AUTOSAR XML (schema 4-3-0)
package /CAN4/ISignalGroup
  12 x i signal group:
    CAN4_SG_FD4_C100_0: i-signal=[CAN4_DCDCEnDemand, CAN4_EACSpdDemand, CAN4_FDC_CHA_EACEnDemand_Cmd, CAN4_FDC_EHPS_EnDemand_Cmd, CAN4_FDC_EHPS_SpdDemand_Cmd, CAN4_VCULife2], system-signal-group=CAN4_SG_FD4_C100_0
    CAN4_SG_FD4_C10_0: i-signal=[CAN4_ACHVPwrOnOffReq, CAN4_MCUHVPwrOnOffReq, CAN4_VCULife1, CAN4_VCU_DCDCEACEHPSRlyEn_cmd, CAN4_VCU_DeFogTMSRlyEn_cmd], system-signal-group=CAN4_SG_FD4_C10_0
    CAN4_SG_FD4_C200_0: i-signal=[CAN4_SysPowerMode, CAN4_VCUIGNSta, CAN4_VCUIRCSta], system-signal-group=CAN4_SG_FD4_C200_0
    CAN4_SG_FD4_CE100_0: i-signal=[CAN4_FDC_BCM_BSD_Buzzer_Cmd, CAN4_FDC_BCM_Brake_Cmd, CAN4_FDC_BCM_CallBell_Cmd, CAN4_FDC_BCM_DVRSignalL_Cmd, CAN4_FDC_BCM_DVRSignalR_Cmd, CAN4_FDC_BCM_EmExitSW_Sta, CAN4_FDC_BCM_EmSV_Cmd, CAN4_FDC_BCM_FDCloseSV_Cmd, CAN4_FDC_BCM_FDOpenSV_Cmd, CAN4_FDC_BCM_FDoor_Sta, CAN4_FDC_BCM_HBeam_Cmd, CAN4_FDC_BCM_InnerBuzzerMode_Sta, CAN4_FDC_BCM_InnerBuzzer_Cmd, CAN4_FDC_BCM_InnerCallBell_Cmd, CAN4_FDC_BCM_LBSDR_Cmd, CAN4_FDC_BCM_LBSDY_Cmd, CAN4_FDC_BCM_LBeam_Cmd, CAN4_FDC_BCM_LDRL_Cmd, CAN4_FDC_BCM_LTurnLp_Cmd, CAN4_FDC_BCM_MDCloseSV_Cmd, CAN4_FDC_BCM_MDOpenSV_Cmd, CAN4_FDC_BCM_MDoor_Sta, CAN4_FDC_BCM_OutDoorOpenSW_Sta, CAN4_FDC_BCM_PLamp_Cmd, CAN4_FDC_BCM_RBSDR_Cmd, CAN4_FDC_BCM_RBSDY_Cmd, CAN4_FDC_BCM_RDRL_Cmd, CAN4_FDC_BCM_RDoor_Sta, CAN4_FDC_BCM_RFLamp_Cmd, CAN4_FDC_BCM_RGear_Sta, CAN4_FDC_BCM_RTurnLp_Cmd, CAN4_FDC_BCM_RoomLpAmb_Cmd, CAN4_FDC_BCM_SLTLp_Cmd, CAN4_FDC_BCM_SMKL_Cmd, CAN4_FDC_BCM_SMKR_Cmd, CAN4_FDC_BCM_SRTLp_Cmd, CAN4_FDC_BCM_STOPBALL_Cmd, CAN4_FDC_BCM_Stop_IND_Cmd, CAN4_FDC_BCM_TurnLpPattern_Sta, CAN4_FDC_BCM_Washer_Cmd, CAN4_FDC_BCM_WiperH_Cmd, CAN4_FDC_BCM_WiperL_Cmd, CAN4_VCUKeyStatus], system-signal-group=CAN4_SG_FD4_CE100_0
    CAN4_SG_FD4_CE100_1: i-signal=[CAN4_FDC_BCM_FRoomLp_Cmd, CAN4_FDC_BCM_MRoomLp_Cmd, CAN4_FDC_BCM_RRoomLp_Cmd, CAN4_FDC_THCM_CoolFanReq_Cmd], system-signal-group=CAN4_SG_FD4_CE100_1
    CAN4_SG_ZFR_C100_0: i-signal=CAN4_ParkBrakeSW, system-signal-group=CAN4_SG_ZFR_C100_0
    CAN4_SG_ZFR_C5000_0: i-signal=[CAN4_ZFR_CHASSIS_LiningWearFL_Sta, CAN4_ZFR_CHASSIS_LiningWearFR_Sta], system-signal-group=CAN4_SG_ZFR_C5000_0
    CAN4_SG_ZFR_CE100_0: i-signal=[CAN4_AirPressureFC2, CAN4_ZFR_BCM_AutoLightSW_Sta, CAN4_ZFR_BCM_BSD_Dimmer_Sta, CAN4_ZFR_BCM_BacklightDuty_Sta, CAN4_ZFR_BCM_Brake_Sta, CAN4_ZFR_BCM_DVRMidDoor_Sta, CAN4_ZFR_BCM_DVRSignalL_Sta, CAN4_ZFR_BCM_DVRSignalR_Sta, CAN4_ZFR_BCM_DVRSignalReverse_Sta, CAN4_ZFR_BCM_HBeamSW_Sta, CAN4_ZFR_BCM_HBeam_Sta, CAN4_ZFR_BCM_HeadLpSW_Sta, CAN4_ZFR_BCM_HornSW_Sta, CAN4_ZFR_BCM_LBSDR_Sta, CAN4_ZFR_BCM_LBSDY_Sta, CAN4_ZFR_BCM_LBeam_Sta, CAN4_ZFR_BCM_LDRL_Sta, CAN4_ZFR_BCM_LFTurnLpC_Sta, CAN4_ZFR_BCM_LFTurnLp_Sta, CAN4_ZFR_BCM_LightSensorV_Sta, CAN4_ZFR_BCM_PLamp_Sta, CAN4_ZFR_BCM_PosLpSW_Sta, CAN4_ZFR_BCM_RBSDR_Sta, CAN4_ZFR_BCM_RBSDY_Sta, CAN4_ZFR_BCM_RDRL_Sta, CAN4_ZFR_BCM_RFTurnLpC_Sta, CAN4_ZFR_BCM_RFTurnLp_Sta, CAN4_ZFR_BCM_RFogLp_SW_Sta, CAN4_ZFR_BCM_Seatbelt_Sta, CAN4_ZFR_BCM_TurnBuzzer_Sta, CAN4_ZFR_BCM_WasherSW_Sta, CAN4_ZFR_BCM_Washer_Sta, CAN4_ZFR_BCM_WiperAS_Sta, CAN4_ZFR_BCM_WiperHSW_Sta, CAN4_ZFR_BCM_WiperH_Sta, CAN4_ZFR_BCM_WiperLSW_Sta, CAN4_ZFR_BCM_WiperL_Sta], system-signal-group=CAN4_SG_ZFR_CE100_0
    CAN4_SG_ZRR_C5000_0: i-signal=[CAN4_ZRR_CHASSIS_LiningWearRL_Sta, CAN4_ZRR_CHASSIS_LiningWearRR_Sta], system-signal-group=CAN4_SG_ZRR_C5000_0
    CAN4_SG_ZRR_CE100_0: i-signal=CAN4_ZRR_BCM_AllDoor_Sta, system-signal-group=CAN4_SG_ZRR_CE100_0
    CAN4_SG_ZRR_CE100_1: i-signal=[CAN4_AirPressurePC3, CAN4_AirPressureRC1, CAN4_FDC_CHASSIS_VCUEACPress_Sta, CAN4_ZRR_BCM_BrakeLp_Sta, CAN4_ZRR_BCM_CallingSW_Sta, CAN4_ZRR_BCM_EmLight_Sta, CAN4_ZRR_BCM_EmSV_Sta, CAN4_ZRR_BCM_FDCloseSV_Sta, CAN4_ZRR_BCM_FDOpenSV_Sta, CAN4_ZRR_BCM_FDoorAP_Sta, CAN4_ZRR_BCM_LRTurnLpC_Sta, CAN4_ZRR_BCM_LRTurnLp_Sta, CAN4_ZRR_BCM_MDCloseSV_Sta, CAN4_ZRR_BCM_MDOpenSV_Sta, CAN4_ZRR_BCM_MDoorAP_Sta, CAN4_ZRR_BCM_PLamp_Sta, CAN4_ZRR_BCM_RFLamp_Sta, CAN4_ZRR_BCM_RRTurnLpC_Sta, CAN4_ZRR_BCM_RRTurnLp_Sta, CAN4_ZRR_BCM_ReverseBuz_Sta, CAN4_ZRR_BCM_ReverseLp_Sta, CAN4_ZRR_BCM_RoomLpAmb_Sta, CAN4_ZRR_BCM_SLTLp_Sta, CAN4_ZRR_BCM_SMKL_Sta, CAN4_ZRR_BCM_SMKR_Sta, CAN4_ZRR_BCM_SRTLp_Sta, CAN4_ZRR_BCM_STOPSW2_Sta, CAN4_ZRR_BCM_STOPSW_Sta, CAN4_ZRR_BCM_StopLight_Sta, CAN4_ZRR_BCM_TurnBuzzer_Sta], system-signal-group=CAN4_SG_ZRR_CE100_1
    CAN4_SG_zGW_CANRr1_C50_0: i-signal=[CAN4_DCDC_En_Sta, CAN4_DCDC_ErrLv_Sta, CAN4_DCDC_LifeSig_Sta, CAN4_DCDC_OutVol_Sta, CAN4_DCDC_Temp_Sta, CAN4_EAC_En_Sta, CAN4_EAC_ErrLv_Sta, CAN4_EAC_InvTemp_Sta, CAN4_EAC_LifeSig_Sta, CAN4_EHPS_En_Sta, CAN4_EHPS_ErrLv_Sta, CAN4_EHPS_InvTemp_Sta, CAN4_EHPS_LifeSig_Sta, CAN4_EHPS_MotorSpd_Sta, CAN4_PDU_ACRly_Sta, CAN4_PDU_DCDCEACEHPSHVLoop_Sta, CAN4_PDU_DCDCEACEHPSPreRly_Sta, CAN4_PDU_DCDCEACEHPSRly_Sta, CAN4_PDU_DeFogTMSRly_Sta, CAN4_PDU_HVIL_Sta, CAN4_PDU_LifeSig_Sta, CAN4_PDU_MCUHVLoop_Sta, CAN4_PDU_MCUPosRly_Sta, CAN4_PDU_MCUPreRly_Sta, CAN4_PDU_SelfChk_Sta], system-signal-group=CAN4_SG_zGW_CANRr1_C50_0
package /CAN4/Cluster
  can cluster CAN4: baudrate=500, can-fd-baudrate=2000
    can physical channel CAN4: comm-connectors=ConnCAN4
      frame CAN4_DiagFuncReqFT: id 0x7D0, frame-length=8, can-addressing-mode=STANDARD, can-fd-frame-support=false, can-frame-rx-behavior=CAN-20, can-frame-tx-behavior=CAN-20
        n pdu CAN4_DiagFuncReqFT: length=8
      frame CAN4_DiagPhysReqToZONE_FR: id 0x684, frame-length=64, can-addressing-mode=STANDARD, can-fd-frame-support=true, can-frame-rx-behavior=CAN-FD, can-frame-tx-behavior=CAN-FD
        n pdu CAN4_DiagPhysReqToZONE_FR: length=8
      frame CAN4_DiagPhysReqToZONE_RR: id 0x6E4, frame-length=64, can-addressing-mode=STANDARD, can-fd-frame-support=true, can-frame-rx-behavior=CAN-FD, can-frame-tx-behavior=CAN-FD
        n pdu CAN4_DiagPhysReqToZONE_RR: length=8
      frame CAN4_DiagRespFromZONE_FR: id 0x604, frame-length=64, can-addressing-mode=STANDARD, can-fd-frame-support=true, can-frame-rx-behavior=CAN-FD, can-frame-tx-behavior=CAN-FD
        n pdu CAN4_DiagRespFromZONE_FR: length=8
      frame CAN4_DiagRespFromZONE_RR: id 0x664, frame-length=64, can-addressing-mode=STANDARD, can-fd-frame-support=true, can-frame-rx-behavior=CAN-FD, can-frame-tx-behavior=CAN-FD
        n pdu CAN4_DiagRespFromZONE_RR: length=8
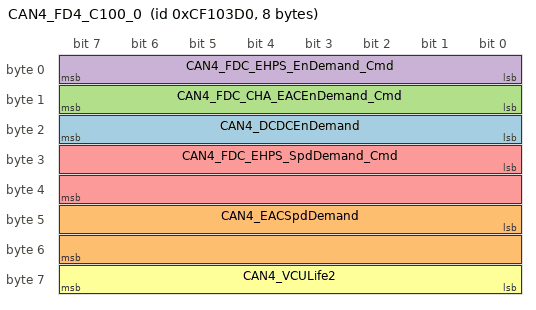
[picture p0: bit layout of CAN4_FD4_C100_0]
      frame CAN4_FD4_C100_0: id 0xCF103D0, frame-length=8, can-addressing-mode=EXTENDED, can-fd-frame-support=false, can-frame-rx-behavior=CAN-20, can-frame-tx-behavior=CAN-20
        pdu CAN4_FD4_C100_0: length=8, minimum-delay=0.0, transmission-mode-true-timing=cyclic-timing=time-period=0.1, unused-bit-pattern=0
          mapping CAN4_SG_FD4_C100_0: i-signal-group=CAN4_SG_FD4_C100_0, start-position=0, transfer-property=PENDING
          signal CAN4_DCDCEnDemand: start 16, 8 bit, little-endian, i-signal-type=PRIMITIVE, init-value=constant-reference=Init_CAN4_DCDCEnDemand, base-type=uint8, implementation-data-type=uint8, transfer-property=PENDING
          signal CAN4_EACSpdDemand: start 40, 16 bit, little-endian, i-signal-type=PRIMITIVE, init-value=constant-reference=Init_CAN4_EACSpdDemand, base-type=uint16, implementation-data-type=uint16, transfer-property=PENDING
          signal CAN4_FDC_CHA_EACEnDemand_Cmd: start 8, 8 bit, little-endian, i-signal-type=PRIMITIVE, init-value=constant-reference=Init_CAN4_FDC_CHA_EACEnDemand_Cmd, base-type=uint8, implementation-data-type=uint8, transfer-property=PENDING
          signal CAN4_FDC_EHPS_EnDemand_Cmd: start 0, 8 bit, little-endian, i-signal-type=PRIMITIVE, init-value=constant-reference=Init_CAN4_FDC_EHPS_EnDemand_Cmd, base-type=uint8, implementation-data-type=uint8, transfer-property=PENDING
          signal CAN4_FDC_EHPS_SpdDemand_Cmd: start 24, 16 bit, little-endian, i-signal-type=PRIMITIVE, init-value=constant-reference=Init_CAN4_FDC_EHPS_SpdDemand_Cmd, base-type=uint16, implementation-data-type=uint16, transfer-property=PENDING
          signal CAN4_VCULife2: start 56, 8 bit, little-endian, i-signal-type=PRIMITIVE, init-value=constant-reference=Init_CAN4_VCULife2, base-type=uint8, implementation-data-type=uint8, transfer-property=PENDING
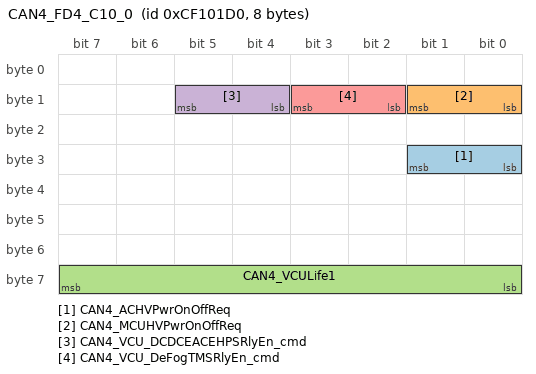
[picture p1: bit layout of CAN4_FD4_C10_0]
      frame CAN4_FD4_C10_0: id 0xCF101D0, frame-length=8, can-addressing-mode=EXTENDED, can-fd-frame-support=false, can-frame-rx-behavior=CAN-20, can-frame-tx-behavior=CAN-20
        pdu CAN4_FD4_C10_0: length=8, minimum-delay=0.0, transmission-mode-true-timing=cyclic-timing=time-period=0.01, unused-bit-pattern=0
          mapping CAN4_SG_FD4_C10_0: i-signal-group=CAN4_SG_FD4_C10_0, start-position=0, transfer-property=PENDING
          signal CAN4_ACHVPwrOnOffReq: start 24, 2 bit, little-endian, i-signal-type=PRIMITIVE, init-value=constant-reference=Init_CAN4_ACHVPwrOnOffReq, base-type=uint8, implementation-data-type=uint8, transfer-property=PENDING
          signal CAN4_MCUHVPwrOnOffReq: start 8, 2 bit, little-endian, i-signal-type=PRIMITIVE, init-value=constant-reference=Init_CAN4_MCUHVPwrOnOffReq, base-type=uint8, implementation-data-type=uint8, transfer-property=PENDING
          signal CAN4_VCULife1: start 56, 8 bit, little-endian, i-signal-type=PRIMITIVE, init-value=constant-reference=Init_CAN4_VCULife1, base-type=uint8, implementation-data-type=uint8, transfer-property=PENDING
          signal CAN4_VCU_DCDCEACEHPSRlyEn_cmd: start 12, 2 bit, little-endian, i-signal-type=PRIMITIVE, init-value=constant-reference=Init_CAN4_VCU_DCDCEACEHPSRlyEn_cmd, base-type=uint8, implementation-data-type=uint8, transfer-property=PENDING
          signal CAN4_VCU_DeFogTMSRlyEn_cmd: start 10, 2 bit, little-endian, i-signal-type=PRIMITIVE, init-value=constant-reference=Init_CAN4_VCU_DeFogTMSRlyEn_cmd, base-type=uint8, implementation-data-type=uint8, transfer-property=PENDING
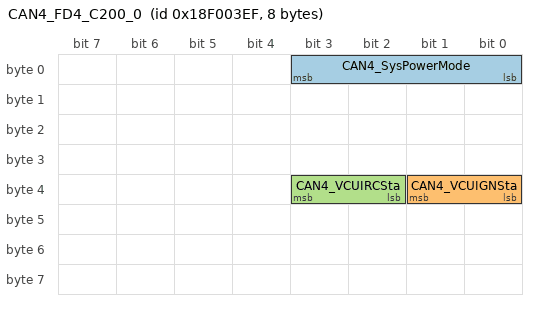
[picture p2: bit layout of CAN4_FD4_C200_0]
      frame CAN4_FD4_C200_0: id 0x18F003EF, frame-length=8, can-addressing-mode=EXTENDED, can-fd-frame-support=false, can-frame-rx-behavior=CAN-20, can-frame-tx-behavior=CAN-20
        pdu CAN4_FD4_C200_0: length=8, minimum-delay=0.0, transmission-mode-true-timing=cyclic-timing=time-period=0.2, unused-bit-pattern=0
          mapping CAN4_SG_FD4_C200_0: i-signal-group=CAN4_SG_FD4_C200_0, start-position=0, transfer-property=PENDING
          signal CAN4_SysPowerMode: start 0, 4 bit, little-endian, i-signal-type=PRIMITIVE, init-value=constant-reference=Init_CAN4_SysPowerMode, base-type=uint8, implementation-data-type=uint8, transfer-property=PENDING
          signal CAN4_VCUIGNSta: start 32, 2 bit, little-endian, i-signal-type=PRIMITIVE, init-value=constant-reference=Init_CAN4_VCUIGNSta, base-type=uint8, implementation-data-type=uint8, transfer-property=PENDING
          signal CAN4_VCUIRCSta: start 34, 2 bit, little-endian, i-signal-type=PRIMITIVE, init-value=constant-reference=Init_CAN4_VCUIRCSta, base-type=uint8, implementation-data-type=uint8, transfer-property=PENDING
      frame CAN4_FD4_CE100_0: id 0x209, frame-length=32, can-addressing-mode=STANDARD, can-fd-frame-support=true, can-frame-rx-behavior=CAN-FD, can-frame-tx-behavior=CAN-FD
        pdu CAN4_FD4_CE100_0: length=32, minimum-delay=0.0, transmission-mode-true-timing={cyclic-timing=time-period=0.1, event-controlled-timing={number-of-repetitions=0, repetition-period=0}}, unused-bit-pattern=0
          mapping CAN4_SG_FD4_CE100_0: i-signal-group=CAN4_SG_FD4_CE100_0, start-position=0, transfer-property=TRIGGERED-ON-CHANGE
          signal CAN4_FDC_BCM_BSD_Buzzer_Cmd: start 39, 1 bit, big-endian, i-signal-type=PRIMITIVE, init-value=constant-reference=Init_CAN4_FDC_BCM_BSD_Buzzer_Cmd, base-type=uint8, implementation-data-type=uint8, transfer-property=TRIGGERED-ON-CHANGE
          signal CAN4_FDC_BCM_Brake_Cmd: start 30, 1 bit, big-endian, i-signal-type=PRIMITIVE, init-value=constant-reference=Init_CAN4_FDC_BCM_Brake_Cmd, base-type=uint8, implementation-data-type=uint8, transfer-property=TRIGGERED-ON-CHANGE
          signal CAN4_FDC_BCM_CallBell_Cmd: start 20, 1 bit, big-endian, i-signal-type=PRIMITIVE, init-value=constant-reference=Init_CAN4_FDC_BCM_CallBell_Cmd, base-type=uint8, implementation-data-type=uint8, transfer-property=TRIGGERED-ON-CHANGE
          signal CAN4_FDC_BCM_DVRSignalL_Cmd: start 52, 1 bit, big-endian, i-signal-type=PRIMITIVE, init-value=constant-reference=Init_CAN4_FDC_BCM_DVRSignalL_Cmd, base-type=uint8, implementation-data-type=uint8, transfer-property=PENDING
          signal CAN4_FDC_BCM_DVRSignalR_Cmd: start 51, 1 bit, big-endian, i-signal-type=PRIMITIVE, init-value=constant-reference=Init_CAN4_FDC_BCM_DVRSignalR_Cmd, base-type=uint8, implementation-data-type=uint8, transfer-property=PENDING
          signal CAN4_FDC_BCM_EmExitSW_Sta: start 9, 1 bit, big-endian, i-signal-type=PRIMITIVE, init-value=constant-reference=Init_CAN4_FDC_BCM_EmExitSW_Sta, base-type=uint8, implementation-data-type=uint8, transfer-property=TRIGGERED-ON-CHANGE
          signal CAN4_FDC_BCM_EmSV_Cmd: start 6, 1 bit, big-endian, i-signal-type=PRIMITIVE, init-value=constant-reference=Init_CAN4_FDC_BCM_EmSV_Cmd, base-type=uint8, implementation-data-type=uint8, transfer-property=TRIGGERED-ON-CHANGE
          signal CAN4_FDC_BCM_FDCloseSV_Cmd: start 3, 1 bit, big-endian, i-signal-type=PRIMITIVE, init-value=constant-reference=Init_CAN4_FDC_BCM_FDCloseSV_Cmd, base-type=uint8, implementation-data-type=uint8, transfer-property=TRIGGERED-ON-CHANGE
          signal CAN4_FDC_BCM_FDOpenSV_Cmd: start 2, 1 bit, big-endian, i-signal-type=PRIMITIVE, init-value=constant-reference=Init_CAN4_FDC_BCM_FDOpenSV_Cmd, base-type=uint8, implementation-data-type=uint8, transfer-property=TRIGGERED-ON-CHANGE
          signal CAN4_FDC_BCM_FDoor_Sta: start 45, 1 bit, big-endian, i-signal-type=PRIMITIVE, init-value=constant-reference=Init_CAN4_FDC_BCM_FDoor_Sta, base-type=uint8, implementation-data-type=uint8, transfer-property=TRIGGERED-ON-CHANGE
          signal CAN4_FDC_BCM_HBeam_Cmd: start 40, 1 bit, big-endian, i-signal-type=PRIMITIVE, init-value=constant-reference=Init_CAN4_FDC_BCM_HBeam_Cmd, base-type=uint8, implementation-data-type=uint8, transfer-property=TRIGGERED-ON-CHANGE
          signal CAN4_FDC_BCM_InnerBuzzerMode_Sta: start 23, 3 bit, big-endian, i-signal-type=PRIMITIVE, init-value=constant-reference=Init_CAN4_FDC_BCM_InnerBuzzerMode_Sta, base-type=uint8, implementation-data-type=uint8, transfer-property=TRIGGERED-ON-CHANGE
          signal CAN4_FDC_BCM_InnerBuzzer_Cmd: start 8, 1 bit, big-endian, i-signal-type=PRIMITIVE, init-value=constant-reference=Init_CAN4_FDC_BCM_InnerBuzzer_Cmd, base-type=uint8, implementation-data-type=uint8, transfer-property=TRIGGERED-ON-CHANGE
          signal CAN4_FDC_BCM_InnerCallBell_Cmd: start 19, 1 bit, big-endian, i-signal-type=PRIMITIVE, init-value=constant-reference=Init_CAN4_FDC_BCM_InnerCallBell_Cmd, base-type=uint8, implementation-data-type=uint8, transfer-property=TRIGGERED-ON-CHANGE
          signal CAN4_FDC_BCM_LBSDR_Cmd: start 35, 1 bit, big-endian, i-signal-type=PRIMITIVE, init-value=constant-reference=Init_CAN4_FDC_BCM_LBSDR_Cmd, base-type=uint8, implementation-data-type=uint8, transfer-property=TRIGGERED-ON-CHANGE
          signal CAN4_FDC_BCM_LBSDY_Cmd: start 36, 1 bit, big-endian, i-signal-type=PRIMITIVE, init-value=constant-reference=Init_CAN4_FDC_BCM_LBSDY_Cmd, base-type=uint8, implementation-data-type=uint8, transfer-property=TRIGGERED-ON-CHANGE
          signal CAN4_FDC_BCM_LBeam_Cmd: start 55, 1 bit, big-endian, i-signal-type=PRIMITIVE, init-value=constant-reference=Init_CAN4_FDC_BCM_LBeam_Cmd, base-type=uint8, implementation-data-type=uint8, transfer-property=TRIGGERED-ON-CHANGE
          signal CAN4_FDC_BCM_LDRL_Cmd: start 42, 1 bit, big-endian, i-signal-type=PRIMITIVE, init-value=constant-reference=Init_CAN4_FDC_BCM_LDRL_Cmd, base-type=uint8, implementation-data-type=uint8, transfer-property=TRIGGERED-ON-CHANGE
          signal CAN4_FDC_BCM_LTurnLp_Cmd: start 54, 1 bit, big-endian, i-signal-type=PRIMITIVE, init-value=constant-reference=Init_CAN4_FDC_BCM_LTurnLp_Cmd, base-type=uint8, implementation-data-type=uint8, transfer-property=PENDING
          signal CAN4_FDC_BCM_MDCloseSV_Cmd: start 5, 1 bit, big-endian, i-signal-type=PRIMITIVE, init-value=constant-reference=Init_CAN4_FDC_BCM_MDCloseSV_Cmd, base-type=uint8, implementation-data-type=uint8, transfer-property=TRIGGERED-ON-CHANGE
          signal CAN4_FDC_BCM_MDOpenSV_Cmd: start 4, 1 bit, big-endian, i-signal-type=PRIMITIVE, init-value=constant-reference=Init_CAN4_FDC_BCM_MDOpenSV_Cmd, base-type=uint8, implementation-data-type=uint8, transfer-property=TRIGGERED-ON-CHANGE
          signal CAN4_FDC_BCM_MDoor_Sta: start 44, 1 bit, big-endian, i-signal-type=PRIMITIVE, init-value=constant-reference=Init_CAN4_FDC_BCM_MDoor_Sta, base-type=uint8, implementation-data-type=uint8, transfer-property=TRIGGERED-ON-CHANGE
          signal CAN4_FDC_BCM_OutDoorOpenSW_Sta: start 1, 2 bit, big-endian, i-signal-type=PRIMITIVE, init-value=constant-reference=Init_CAN4_FDC_BCM_OutDoorOpenSW_Sta, base-type=uint8, implementation-data-type=uint8, transfer-property=TRIGGERED-ON-CHANGE
          signal CAN4_FDC_BCM_PLamp_Cmd: start 41, 1 bit, big-endian, i-signal-type=PRIMITIVE, init-value=constant-reference=Init_CAN4_FDC_BCM_PLamp_Cmd, base-type=uint8, implementation-data-type=uint8, transfer-property=TRIGGERED-ON-CHANGE
          signal CAN4_FDC_BCM_RBSDR_Cmd: start 37, 1 bit, big-endian, i-signal-type=PRIMITIVE, init-value=constant-reference=Init_CAN4_FDC_BCM_RBSDR_Cmd, base-type=uint8, implementation-data-type=uint8, transfer-property=TRIGGERED-ON-CHANGE
          signal CAN4_FDC_BCM_RBSDY_Cmd: start 38, 1 bit, big-endian, i-signal-type=PRIMITIVE, init-value=constant-reference=Init_CAN4_FDC_BCM_RBSDY_Cmd, base-type=uint8, implementation-data-type=uint8, transfer-property=TRIGGERED-ON-CHANGE
          signal CAN4_FDC_BCM_RDRL_Cmd: start 43, 1 bit, big-endian, i-signal-type=PRIMITIVE, init-value=constant-reference=Init_CAN4_FDC_BCM_RDRL_Cmd, base-type=uint8, implementation-data-type=uint8, transfer-property=TRIGGERED-ON-CHANGE
          signal CAN4_FDC_BCM_RDoor_Sta: start 46, 1 bit, big-endian, i-signal-type=PRIMITIVE, init-value=constant-reference=Init_CAN4_FDC_BCM_RDoor_Sta, base-type=uint8, implementation-data-type=uint8, transfer-property=TRIGGERED-ON-CHANGE
          signal CAN4_FDC_BCM_RFLamp_Cmd: start 31, 1 bit, big-endian, i-signal-type=PRIMITIVE, init-value=constant-reference=Init_CAN4_FDC_BCM_RFLamp_Cmd, base-type=uint8, implementation-data-type=uint8, transfer-property=TRIGGERED-ON-CHANGE
          signal CAN4_FDC_BCM_RGear_Sta: start 47, 1 bit, big-endian, i-signal-type=PRIMITIVE, init-value=constant-reference=Init_CAN4_FDC_BCM_RGear_Sta, base-type=uint8, implementation-data-type=uint8, transfer-property=TRIGGERED-ON-CHANGE
          signal CAN4_FDC_BCM_RTurnLp_Cmd: start 53, 1 bit, big-endian, i-signal-type=PRIMITIVE, init-value=constant-reference=Init_CAN4_FDC_BCM_RTurnLp_Cmd, base-type=uint8, implementation-data-type=uint8, transfer-property=PENDING
          signal CAN4_FDC_BCM_RoomLpAmb_Cmd: start 25, 1 bit, big-endian, i-signal-type=PRIMITIVE, init-value=constant-reference=Init_CAN4_FDC_BCM_RoomLpAmb_Cmd, base-type=uint8, implementation-data-type=uint8, transfer-property=TRIGGERED-ON-CHANGE
          signal CAN4_FDC_BCM_SLTLp_Cmd: start 29, 1 bit, big-endian, i-signal-type=PRIMITIVE, init-value=constant-reference=Init_CAN4_FDC_BCM_SLTLp_Cmd, base-type=uint8, implementation-data-type=uint8, transfer-property=TRIGGERED-ON-CHANGE
          signal CAN4_FDC_BCM_SMKL_Cmd: start 26, 1 bit, big-endian, i-signal-type=PRIMITIVE, init-value=constant-reference=Init_CAN4_FDC_BCM_SMKL_Cmd, base-type=uint8, implementation-data-type=uint8, transfer-property=TRIGGERED-ON-CHANGE
          signal CAN4_FDC_BCM_SMKR_Cmd: start 27, 1 bit, big-endian, i-signal-type=PRIMITIVE, init-value=constant-reference=Init_CAN4_FDC_BCM_SMKR_Cmd, base-type=uint8, implementation-data-type=uint8, transfer-property=TRIGGERED-ON-CHANGE
          signal CAN4_FDC_BCM_SRTLp_Cmd: start 28, 1 bit, big-endian, i-signal-type=PRIMITIVE, init-value=constant-reference=Init_CAN4_FDC_BCM_SRTLp_Cmd, base-type=uint8, implementation-data-type=uint8, transfer-property=TRIGGERED-ON-CHANGE
          signal CAN4_FDC_BCM_STOPBALL_Cmd: start 18, 1 bit, big-endian, i-signal-type=PRIMITIVE, init-value=constant-reference=Init_CAN4_FDC_BCM_STOPBALL_Cmd, base-type=uint8, implementation-data-type=uint8, transfer-property=TRIGGERED-ON-CHANGE
          signal CAN4_FDC_BCM_Stop_IND_Cmd: start 24, 1 bit, big-endian, i-signal-type=PRIMITIVE, init-value=constant-reference=Init_CAN4_FDC_BCM_Stop_IND_Cmd, base-type=uint8, implementation-data-type=uint8, transfer-property=TRIGGERED-ON-CHANGE
          signal CAN4_FDC_BCM_TurnLpPattern_Sta: start 17, 2 bit, big-endian, i-signal-type=PRIMITIVE, init-value=constant-reference=Init_CAN4_FDC_BCM_TurnLpPattern_Sta, base-type=uint8, implementation-data-type=uint8, transfer-property=TRIGGERED-ON-CHANGE
          signal CAN4_FDC_BCM_Washer_Cmd: start 34, 1 bit, big-endian, i-signal-type=PRIMITIVE, init-value=constant-reference=Init_CAN4_FDC_BCM_Washer_Cmd, base-type=uint8, implementation-data-type=uint8, transfer-property=TRIGGERED-ON-CHANGE
          signal CAN4_FDC_BCM_WiperH_Cmd: start 32, 1 bit, big-endian, i-signal-type=PRIMITIVE, init-value=constant-reference=Init_CAN4_FDC_BCM_WiperH_Cmd, base-type=uint8, implementation-data-type=uint8, transfer-property=TRIGGERED-ON-CHANGE
          signal CAN4_FDC_BCM_WiperL_Cmd: start 33, 1 bit, big-endian, i-signal-type=PRIMITIVE, init-value=constant-reference=Init_CAN4_FDC_BCM_WiperL_Cmd, base-type=uint8, implementation-data-type=uint8, transfer-property=TRIGGERED-ON-CHANGE
          signal CAN4_VCUKeyStatus: start 11, 2 bit, big-endian, i-signal-type=PRIMITIVE, init-value=constant-reference=Init_CAN4_VCUKeyStatus, base-type=uint8, implementation-data-type=uint8, transfer-property=PENDING
      frame CAN4_FD4_CE100_1: id 0x210, frame-length=32, can-addressing-mode=STANDARD, can-fd-frame-support=true, can-frame-rx-behavior=CAN-FD, can-frame-tx-behavior=CAN-FD
        pdu CAN4_FD4_CE100_1: length=32, minimum-delay=0.0, transmission-mode-true-timing={cyclic-timing=time-period=0.1, event-controlled-timing={number-of-repetitions=0, repetition-period=0}}, unused-bit-pattern=0
          mapping CAN4_SG_FD4_CE100_1: i-signal-group=CAN4_SG_FD4_CE100_1, start-position=0, transfer-property=TRIGGERED-ON-CHANGE
          signal CAN4_FDC_BCM_FRoomLp_Cmd: start 39, 7 bit, big-endian, i-signal-type=PRIMITIVE, init-value=constant-reference=Init_CAN4_FDC_BCM_FRoomLp_Cmd, base-type=uint8, implementation-data-type=uint8, transfer-property=PENDING
          signal CAN4_FDC_BCM_MRoomLp_Cmd: start 47, 7 bit, big-endian, i-signal-type=PRIMITIVE, init-value=constant-reference=Init_CAN4_FDC_BCM_MRoomLp_Cmd, base-type=uint8, implementation-data-type=uint8, transfer-property=PENDING
          signal CAN4_FDC_BCM_RRoomLp_Cmd: start 7, 7 bit, big-endian, i-signal-type=PRIMITIVE, init-value=constant-reference=Init_CAN4_FDC_BCM_RRoomLp_Cmd, base-type=uint8, implementation-data-type=uint8, transfer-property=PENDING
          signal CAN4_FDC_THCM_CoolFanReq_Cmd: start 15, 8 bit, big-endian, i-signal-type=PRIMITIVE, init-value=constant-reference=Init_CAN4_FDC_THCM_CoolFanReq_Cmd, base-type=uint8, implementation-data-type=uint8, transfer-property=TRIGGERED-ON-CHANGE
      frame CAN4_ZFR_C100_0: id 0x203, frame-length=32, can-addressing-mode=STANDARD, can-fd-frame-support=true, can-frame-rx-behavior=CAN-FD, can-frame-tx-behavior=CAN-FD
        pdu CAN4_ZFR_C100_0: length=32, minimum-delay=0.0, transmission-mode-true-timing=cyclic-timing=time-period=0.1, unused-bit-pattern=0
          mapping CAN4_SG_ZFR_C100_0: i-signal-group=CAN4_SG_ZFR_C100_0, start-position=0, transfer-property=PENDING
          signal CAN4_ParkBrakeSW: start 7, 2 bit, big-endian, i-signal-type=PRIMITIVE, init-value=constant-reference=Init_CAN4_ParkBrakeSW, base-type=uint8, implementation-data-type=uint8, transfer-property=PENDING
      frame CAN4_ZFR_C5000_0: id 0x201, frame-length=32, can-addressing-mode=STANDARD, can-fd-frame-support=true, can-frame-rx-behavior=CAN-FD, can-frame-tx-behavior=CAN-FD
        pdu CAN4_ZFR_C5000_0: length=32, minimum-delay=0.0, transmission-mode-true-timing=cyclic-timing=time-period=5, unused-bit-pattern=0
          mapping CAN4_SG_ZFR_C5000_0: i-signal-group=CAN4_SG_ZFR_C5000_0, start-position=0, transfer-property=PENDING
          signal CAN4_ZFR_CHASSIS_LiningWearFL_Sta: start 7, 1 bit, big-endian, i-signal-type=PRIMITIVE, init-value=constant-reference=Init_CAN4_ZFR_CHASSIS_LiningWearFL_Sta, base-type=uint8, implementation-data-type=uint8, transfer-property=PENDING
          signal CAN4_ZFR_CHASSIS_LiningWearFR_Sta: start 6, 1 bit, big-endian, i-signal-type=PRIMITIVE, init-value=constant-reference=Init_CAN4_ZFR_CHASSIS_LiningWearFR_Sta, base-type=uint8, implementation-data-type=uint8, transfer-property=PENDING
      frame CAN4_ZFR_CE100_0: id 0x205, frame-length=32, can-addressing-mode=STANDARD, can-fd-frame-support=true, can-frame-rx-behavior=CAN-FD, can-frame-tx-behavior=CAN-FD
        pdu CAN4_ZFR_CE100_0: length=32, minimum-delay=0.0, transmission-mode-true-timing={cyclic-timing=time-period=0.1, event-controlled-timing={number-of-repetitions=0, repetition-period=0}}, unused-bit-pattern=0
          mapping CAN4_SG_ZFR_CE100_0: i-signal-group=CAN4_SG_ZFR_CE100_0, start-position=0, transfer-property=TRIGGERED-ON-CHANGE
          signal CAN4_AirPressureFC2: start 79, 8 bit, big-endian, i-signal-type=PRIMITIVE, init-value=constant-reference=Init_CAN4_AirPressureFC2, base-type=uint8, implementation-data-type=uint8, transfer-property=PENDING
          signal CAN4_ZFR_BCM_AutoLightSW_Sta: start 39, 1 bit, big-endian, i-signal-type=PRIMITIVE, init-value=constant-reference=Init_CAN4_ZFR_BCM_AutoLightSW_Sta, base-type=uint8, implementation-data-type=uint8, transfer-property=TRIGGERED-ON-CHANGE
          signal CAN4_ZFR_BCM_BSD_Dimmer_Sta: start 63, 7 bit, big-endian, i-signal-type=PRIMITIVE, init-value=constant-reference=Init_CAN4_ZFR_BCM_BSD_Dimmer_Sta, base-type=uint8, implementation-data-type=uint8, transfer-property=TRIGGERED-ON-CHANGE
          signal CAN4_ZFR_BCM_BacklightDuty_Sta: start 71, 7 bit, big-endian, i-signal-type=PRIMITIVE, init-value=constant-reference=Init_CAN4_ZFR_BCM_BacklightDuty_Sta, base-type=uint8, implementation-data-type=uint8, transfer-property=PENDING
          signal CAN4_ZFR_BCM_Brake_Sta: start 6, 1 bit, big-endian, i-signal-type=PRIMITIVE, init-value=constant-reference=Init_CAN4_ZFR_BCM_Brake_Sta, base-type=uint8, implementation-data-type=uint8, transfer-property=TRIGGERED-ON-CHANGE
          signal CAN4_ZFR_BCM_DVRMidDoor_Sta: start 9, 1 bit, big-endian, i-signal-type=PRIMITIVE, init-value=constant-reference=Init_CAN4_ZFR_BCM_DVRMidDoor_Sta, base-type=uint8, implementation-data-type=uint8, transfer-property=TRIGGERED-ON-CHANGE
          signal CAN4_ZFR_BCM_DVRSignalL_Sta: start 4, 1 bit, big-endian, i-signal-type=PRIMITIVE, init-value=constant-reference=Init_CAN4_ZFR_BCM_DVRSignalL_Sta, base-type=uint8, implementation-data-type=uint8, transfer-property=TRIGGERED-ON-CHANGE
          signal CAN4_ZFR_BCM_DVRSignalR_Sta: start 5, 1 bit, big-endian, i-signal-type=PRIMITIVE, init-value=constant-reference=Init_CAN4_ZFR_BCM_DVRSignalR_Sta, base-type=uint8, implementation-data-type=uint8, transfer-property=TRIGGERED-ON-CHANGE
          signal CAN4_ZFR_BCM_DVRSignalReverse_Sta: start 32, 1 bit, big-endian, i-signal-type=PRIMITIVE, init-value=constant-reference=Init_CAN4_ZFR_BCM_DVRSignalReverse_Sta, base-type=uint8, implementation-data-type=uint8, transfer-property=TRIGGERED-ON-CHANGE
          signal CAN4_ZFR_BCM_HBeamSW_Sta: start 16, 1 bit, big-endian, i-signal-type=PRIMITIVE, init-value=constant-reference=Init_CAN4_ZFR_BCM_HBeamSW_Sta, base-type=uint8, implementation-data-type=uint8, transfer-property=TRIGGERED-ON-CHANGE
          signal CAN4_ZFR_BCM_HBeam_Sta: start 18, 1 bit, big-endian, i-signal-type=PRIMITIVE, init-value=constant-reference=Init_CAN4_ZFR_BCM_HBeam_Sta, base-type=uint8, implementation-data-type=uint8, transfer-property=TRIGGERED-ON-CHANGE
          signal CAN4_ZFR_BCM_HeadLpSW_Sta: start 37, 1 bit, big-endian, i-signal-type=PRIMITIVE, init-value=constant-reference=Init_CAN4_ZFR_BCM_HeadLpSW_Sta, base-type=uint8, implementation-data-type=uint8, transfer-property=TRIGGERED-ON-CHANGE
          signal CAN4_ZFR_BCM_HornSW_Sta: start 33, 1 bit, big-endian, i-signal-type=PRIMITIVE, init-value=constant-reference=Init_CAN4_ZFR_BCM_HornSW_Sta, base-type=uint8, implementation-data-type=uint8, transfer-property=TRIGGERED-ON-CHANGE
          signal CAN4_ZFR_BCM_LBSDR_Sta: start 15, 1 bit, big-endian, i-signal-type=PRIMITIVE, init-value=constant-reference=Init_CAN4_ZFR_BCM_LBSDR_Sta, base-type=uint8, implementation-data-type=uint8, transfer-property=TRIGGERED-ON-CHANGE
          signal CAN4_ZFR_BCM_LBSDY_Sta: start 1, 1 bit, big-endian, i-signal-type=PRIMITIVE, init-value=constant-reference=Init_CAN4_ZFR_BCM_LBSDY_Sta, base-type=uint8, implementation-data-type=uint8, transfer-property=TRIGGERED-ON-CHANGE
          signal CAN4_ZFR_BCM_LBeam_Sta: start 17, 1 bit, big-endian, i-signal-type=PRIMITIVE, init-value=constant-reference=Init_CAN4_ZFR_BCM_LBeam_Sta, base-type=uint8, implementation-data-type=uint8, transfer-property=TRIGGERED-ON-CHANGE
          signal CAN4_ZFR_BCM_LDRL_Sta: start 21, 1 bit, big-endian, i-signal-type=PRIMITIVE, init-value=constant-reference=Init_CAN4_ZFR_BCM_LDRL_Sta, base-type=uint8, implementation-data-type=uint8, transfer-property=TRIGGERED-ON-CHANGE
          signal CAN4_ZFR_BCM_LFTurnLpC_Sta: start 55, 8 bit, big-endian, i-signal-type=PRIMITIVE, init-value=constant-reference=Init_CAN4_ZFR_BCM_LFTurnLpC_Sta, base-type=uint8, implementation-data-type=uint8, transfer-property=TRIGGERED-ON-CHANGE
          signal CAN4_ZFR_BCM_LFTurnLp_Sta: start 23, 1 bit, big-endian, i-signal-type=PRIMITIVE, init-value=constant-reference=Init_CAN4_ZFR_BCM_LFTurnLp_Sta, base-type=uint8, implementation-data-type=uint8, transfer-property=TRIGGERED-ON-CHANGE
          signal CAN4_ZFR_BCM_LightSensorV_Sta: start 31, 8 bit, big-endian, i-signal-type=PRIMITIVE, init-value=constant-reference=Init_CAN4_ZFR_BCM_LightSensorV_Sta, base-type=uint8, implementation-data-type=uint8, transfer-property=TRIGGERED-ON-CHANGE
          signal CAN4_ZFR_BCM_PLamp_Sta: start 19, 1 bit, big-endian, i-signal-type=PRIMITIVE, init-value=constant-reference=Init_CAN4_ZFR_BCM_PLamp_Sta, base-type=uint8, implementation-data-type=uint8, transfer-property=TRIGGERED-ON-CHANGE
          signal CAN4_ZFR_BCM_PosLpSW_Sta: start 38, 1 bit, big-endian, i-signal-type=PRIMITIVE, init-value=constant-reference=Init_CAN4_ZFR_BCM_PosLpSW_Sta, base-type=uint8, implementation-data-type=uint8, transfer-property=TRIGGERED-ON-CHANGE
          signal CAN4_ZFR_BCM_RBSDR_Sta: start 0, 1 bit, big-endian, i-signal-type=PRIMITIVE, init-value=constant-reference=Init_CAN4_ZFR_BCM_RBSDR_Sta, base-type=uint8, implementation-data-type=uint8, transfer-property=TRIGGERED-ON-CHANGE
          signal CAN4_ZFR_BCM_RBSDY_Sta: start 2, 1 bit, big-endian, i-signal-type=PRIMITIVE, init-value=constant-reference=Init_CAN4_ZFR_BCM_RBSDY_Sta, base-type=uint8, implementation-data-type=uint8, transfer-property=TRIGGERED-ON-CHANGE
          signal CAN4_ZFR_BCM_RDRL_Sta: start 22, 1 bit, big-endian, i-signal-type=PRIMITIVE, init-value=constant-reference=Init_CAN4_ZFR_BCM_RDRL_Sta, base-type=uint8, implementation-data-type=uint8, transfer-property=TRIGGERED-ON-CHANGE
          signal CAN4_ZFR_BCM_RFTurnLpC_Sta: start 47, 8 bit, big-endian, i-signal-type=PRIMITIVE, init-value=constant-reference=Init_CAN4_ZFR_BCM_RFTurnLpC_Sta, base-type=uint8, implementation-data-type=uint8, transfer-property=TRIGGERED-ON-CHANGE
          signal CAN4_ZFR_BCM_RFTurnLp_Sta: start 8, 1 bit, big-endian, i-signal-type=PRIMITIVE, init-value=constant-reference=Init_CAN4_ZFR_BCM_RFTurnLp_Sta, base-type=uint8, implementation-data-type=uint8, transfer-property=TRIGGERED-ON-CHANGE
          signal CAN4_ZFR_BCM_RFogLp_SW_Sta: start 14, 1 bit, big-endian, i-signal-type=PRIMITIVE, init-value=constant-reference=Init_CAN4_ZFR_BCM_RFogLp_SW_Sta, base-type=uint8, implementation-data-type=uint8, transfer-property=TRIGGERED-ON-CHANGE
          signal CAN4_ZFR_BCM_Seatbelt_Sta: start 7, 1 bit, big-endian, i-signal-type=PRIMITIVE, init-value=constant-reference=Init_CAN4_ZFR_BCM_Seatbelt_Sta, base-type=uint8, implementation-data-type=uint8, transfer-property=TRIGGERED-ON-CHANGE
          signal CAN4_ZFR_BCM_TurnBuzzer_Sta: start 3, 1 bit, big-endian, i-signal-type=PRIMITIVE, init-value=constant-reference=Init_CAN4_ZFR_BCM_TurnBuzzer_Sta, base-type=uint8, implementation-data-type=uint8, transfer-property=TRIGGERED-ON-CHANGE
          signal CAN4_ZFR_BCM_WasherSW_Sta: start 34, 1 bit, big-endian, i-signal-type=PRIMITIVE, init-value=constant-reference=Init_CAN4_ZFR_BCM_WasherSW_Sta, base-type=uint8, implementation-data-type=uint8, transfer-property=TRIGGERED-ON-CHANGE
          signal CAN4_ZFR_BCM_Washer_Sta: start 13, 1 bit, big-endian, i-signal-type=PRIMITIVE, init-value=constant-reference=Init_CAN4_ZFR_BCM_Washer_Sta, base-type=uint8, implementation-data-type=uint8, transfer-property=TRIGGERED-ON-CHANGE
          signal CAN4_ZFR_BCM_WiperAS_Sta: start 12, 1 bit, big-endian, i-signal-type=PRIMITIVE, init-value=constant-reference=Init_CAN4_ZFR_BCM_WiperAS_Sta, base-type=uint8, implementation-data-type=uint8, transfer-property=TRIGGERED-ON-CHANGE
          signal CAN4_ZFR_BCM_WiperHSW_Sta: start 36, 1 bit, big-endian, i-signal-type=PRIMITIVE, init-value=constant-reference=Init_CAN4_ZFR_BCM_WiperHSW_Sta, base-type=uint8, implementation-data-type=uint8, transfer-property=TRIGGERED-ON-CHANGE
          signal CAN4_ZFR_BCM_WiperH_Sta: start 10, 1 bit, big-endian, i-signal-type=PRIMITIVE, init-value=constant-reference=Init_CAN4_ZFR_BCM_WiperH_Sta, base-type=uint8, implementation-data-type=uint8, transfer-property=TRIGGERED-ON-CHANGE
          signal CAN4_ZFR_BCM_WiperLSW_Sta: start 35, 1 bit, big-endian, i-signal-type=PRIMITIVE, init-value=constant-reference=Init_CAN4_ZFR_BCM_WiperLSW_Sta, base-type=uint8, implementation-data-type=uint8, transfer-property=TRIGGERED-ON-CHANGE
          signal CAN4_ZFR_BCM_WiperL_Sta: start 11, 1 bit, big-endian, i-signal-type=PRIMITIVE, init-value=constant-reference=Init_CAN4_ZFR_BCM_WiperL_Sta, base-type=uint8, implementation-data-type=uint8, transfer-property=TRIGGERED-ON-CHANGE
      frame CAN4_ZRR_C5000_0: id 0x202, frame-length=32, can-addressing-mode=STANDARD, can-fd-frame-support=true, can-frame-rx-behavior=CAN-FD, can-frame-tx-behavior=CAN-FD
        pdu CAN4_ZRR_C5000_0: length=32, minimum-delay=0.0, transmission-mode-true-timing=cyclic-timing=time-period=5, unused-bit-pattern=0
          mapping CAN4_SG_ZRR_C5000_0: i-signal-group=CAN4_SG_ZRR_C5000_0, start-position=0, transfer-property=PENDING
          signal CAN4_ZRR_CHASSIS_LiningWearRL_Sta: start 6, 1 bit, big-endian, i-signal-type=PRIMITIVE, init-value=constant-reference=Init_CAN4_ZRR_CHASSIS_LiningWearRL_Sta, base-type=uint8, implementation-data-type=uint8, transfer-property=PENDING
          signal CAN4_ZRR_CHASSIS_LiningWearRR_Sta: start 7, 1 bit, big-endian, i-signal-type=PRIMITIVE, init-value=constant-reference=Init_CAN4_ZRR_CHASSIS_LiningWearRR_Sta, base-type=uint8, implementation-data-type=uint8, transfer-property=PENDING
      frame CAN4_ZRR_CE100_0: id 0x18FE4EEC, frame-length=8, can-addressing-mode=EXTENDED, can-fd-frame-support=false, can-frame-rx-behavior=CAN-20, can-frame-tx-behavior=CAN-20
        pdu CAN4_ZRR_CE100_0: length=8, minimum-delay=0.0, transmission-mode-true-timing={cyclic-timing=time-period=0.1, event-controlled-timing={number-of-repetitions=0, repetition-period=0}}, unused-bit-pattern=0
          mapping CAN4_SG_ZRR_CE100_0: i-signal-group=CAN4_SG_ZRR_CE100_0, start-position=0, transfer-property=TRIGGERED-ON-CHANGE
          signal CAN4_ZRR_BCM_AllDoor_Sta: start 0, 4 bit, little-endian, i-signal-type=PRIMITIVE, init-value=constant-reference=Init_CAN4_ZRR_BCM_AllDoor_Sta, base-type=uint8, implementation-data-type=uint8, transfer-property=TRIGGERED-ON-CHANGE
      frame CAN4_ZRR_CE100_1: id 0x206, frame-length=32, can-addressing-mode=STANDARD, can-fd-frame-support=true, can-frame-rx-behavior=CAN-FD, can-frame-tx-behavior=CAN-FD
        pdu CAN4_ZRR_CE100_1: length=32, minimum-delay=0.0, transmission-mode-true-timing={cyclic-timing=time-period=0.1, event-controlled-timing={number-of-repetitions=0, repetition-period=0}}, unused-bit-pattern=0
          mapping CAN4_SG_ZRR_CE100_1: i-signal-group=CAN4_SG_ZRR_CE100_1, start-position=0, transfer-property=TRIGGERED-ON-CHANGE
          signal CAN4_AirPressurePC3: start 47, 8 bit, big-endian, i-signal-type=PRIMITIVE, init-value=constant-reference=Init_CAN4_AirPressurePC3, base-type=uint8, implementation-data-type=uint8, transfer-property=PENDING
          signal CAN4_AirPressureRC1: start 55, 8 bit, big-endian, i-signal-type=PRIMITIVE, init-value=constant-reference=Init_CAN4_AirPressureRC1, base-type=uint8, implementation-data-type=uint8, transfer-property=PENDING
          signal CAN4_FDC_CHASSIS_VCUEACPress_Sta: start 71, 1 bit, big-endian, i-signal-type=PRIMITIVE, init-value=constant-reference=Init_CAN4_FDC_CHASSIS_VCUEACPress_Sta, base-type=uint8, implementation-data-type=uint8, transfer-property=PENDING
          signal CAN4_ZRR_BCM_BrakeLp_Sta: start 13, 1 bit, big-endian, i-signal-type=PRIMITIVE, init-value=constant-reference=Init_CAN4_ZRR_BCM_BrakeLp_Sta, base-type=uint8, implementation-data-type=uint8, transfer-property=TRIGGERED-ON-CHANGE
          signal CAN4_ZRR_BCM_CallingSW_Sta: start 8, 1 bit, big-endian, i-signal-type=PRIMITIVE, init-value=constant-reference=Init_CAN4_ZRR_BCM_CallingSW_Sta, base-type=uint8, implementation-data-type=uint8, transfer-property=TRIGGERED-ON-CHANGE
          signal CAN4_ZRR_BCM_EmLight_Sta: start 63, 1 bit, big-endian, i-signal-type=PRIMITIVE, init-value=constant-reference=Init_CAN4_ZRR_BCM_EmLight_Sta, base-type=uint8, implementation-data-type=uint8, transfer-property=PENDING
          signal CAN4_ZRR_BCM_EmSV_Sta: start 7, 1 bit, big-endian, i-signal-type=PRIMITIVE, init-value=constant-reference=Init_CAN4_ZRR_BCM_EmSV_Sta, base-type=uint8, implementation-data-type=uint8, transfer-property=TRIGGERED-ON-CHANGE
          signal CAN4_ZRR_BCM_FDCloseSV_Sta: start 2, 1 bit, big-endian, i-signal-type=PRIMITIVE, init-value=constant-reference=Init_CAN4_ZRR_BCM_FDCloseSV_Sta, base-type=uint8, implementation-data-type=uint8, transfer-property=TRIGGERED-ON-CHANGE
          signal CAN4_ZRR_BCM_FDOpenSV_Sta: start 1, 1 bit, big-endian, i-signal-type=PRIMITIVE, init-value=constant-reference=Init_CAN4_ZRR_BCM_FDOpenSV_Sta, base-type=uint8, implementation-data-type=uint8, transfer-property=TRIGGERED-ON-CHANGE
          signal CAN4_ZRR_BCM_FDoorAP_Sta: start 5, 1 bit, big-endian, i-signal-type=PRIMITIVE, init-value=constant-reference=Init_CAN4_ZRR_BCM_FDoorAP_Sta, base-type=uint8, implementation-data-type=uint8, transfer-property=TRIGGERED-ON-CHANGE
          signal CAN4_ZRR_BCM_LRTurnLpC_Sta: start 31, 8 bit, big-endian, i-signal-type=PRIMITIVE, init-value=constant-reference=Init_CAN4_ZRR_BCM_LRTurnLpC_Sta, base-type=uint8, implementation-data-type=uint8, transfer-property=TRIGGERED-ON-CHANGE
          signal CAN4_ZRR_BCM_LRTurnLp_Sta: start 9, 1 bit, big-endian, i-signal-type=PRIMITIVE, init-value=constant-reference=Init_CAN4_ZRR_BCM_LRTurnLp_Sta, base-type=uint8, implementation-data-type=uint8, transfer-property=TRIGGERED-ON-CHANGE
          signal CAN4_ZRR_BCM_MDCloseSV_Sta: start 4, 1 bit, big-endian, i-signal-type=PRIMITIVE, init-value=constant-reference=Init_CAN4_ZRR_BCM_MDCloseSV_Sta, base-type=uint8, implementation-data-type=uint8, transfer-property=TRIGGERED-ON-CHANGE
          signal CAN4_ZRR_BCM_MDOpenSV_Sta: start 3, 1 bit, big-endian, i-signal-type=PRIMITIVE, init-value=constant-reference=Init_CAN4_ZRR_BCM_MDOpenSV_Sta, base-type=uint8, implementation-data-type=uint8, transfer-property=TRIGGERED-ON-CHANGE
          signal CAN4_ZRR_BCM_MDoorAP_Sta: start 6, 1 bit, big-endian, i-signal-type=PRIMITIVE, init-value=constant-reference=Init_CAN4_ZRR_BCM_MDoorAP_Sta, base-type=uint8, implementation-data-type=uint8, transfer-property=TRIGGERED-ON-CHANGE
          signal CAN4_ZRR_BCM_PLamp_Sta: start 14, 1 bit, big-endian, i-signal-type=PRIMITIVE, init-value=constant-reference=Init_CAN4_ZRR_BCM_PLamp_Sta, base-type=uint8, implementation-data-type=uint8, transfer-property=TRIGGERED-ON-CHANGE
          signal CAN4_ZRR_BCM_RFLamp_Sta: start 12, 1 bit, big-endian, i-signal-type=PRIMITIVE, init-value=constant-reference=Init_CAN4_ZRR_BCM_RFLamp_Sta, base-type=uint8, implementation-data-type=uint8, transfer-property=TRIGGERED-ON-CHANGE
          signal CAN4_ZRR_BCM_RRTurnLpC_Sta: start 23, 8 bit, big-endian, i-signal-type=PRIMITIVE, init-value=constant-reference=Init_CAN4_ZRR_BCM_RRTurnLpC_Sta, base-type=uint8, implementation-data-type=uint8, transfer-property=TRIGGERED-ON-CHANGE
          signal CAN4_ZRR_BCM_RRTurnLp_Sta: start 10, 1 bit, big-endian, i-signal-type=PRIMITIVE, init-value=constant-reference=Init_CAN4_ZRR_BCM_RRTurnLp_Sta, base-type=uint8, implementation-data-type=uint8, transfer-property=TRIGGERED-ON-CHANGE
          signal CAN4_ZRR_BCM_ReverseBuz_Sta: start 0, 1 bit, big-endian, i-signal-type=PRIMITIVE, init-value=constant-reference=Init_CAN4_ZRR_BCM_ReverseBuz_Sta, base-type=uint8, implementation-data-type=uint8, transfer-property=TRIGGERED-ON-CHANGE
          signal CAN4_ZRR_BCM_ReverseLp_Sta: start 15, 1 bit, big-endian, i-signal-type=PRIMITIVE, init-value=constant-reference=Init_CAN4_ZRR_BCM_ReverseLp_Sta, base-type=uint8, implementation-data-type=uint8, transfer-property=TRIGGERED-ON-CHANGE
          signal CAN4_ZRR_BCM_RoomLpAmb_Sta: start 33, 1 bit, big-endian, i-signal-type=PRIMITIVE, init-value=constant-reference=Init_CAN4_ZRR_BCM_RoomLpAmb_Sta, base-type=uint8, implementation-data-type=uint8, transfer-property=TRIGGERED-ON-CHANGE
          signal CAN4_ZRR_BCM_SLTLp_Sta: start 37, 1 bit, big-endian, i-signal-type=PRIMITIVE, init-value=constant-reference=Init_CAN4_ZRR_BCM_SLTLp_Sta, base-type=uint8, implementation-data-type=uint8, transfer-property=TRIGGERED-ON-CHANGE
          signal CAN4_ZRR_BCM_SMKL_Sta: start 34, 1 bit, big-endian, i-signal-type=PRIMITIVE, init-value=constant-reference=Init_CAN4_ZRR_BCM_SMKL_Sta, base-type=uint8, implementation-data-type=uint8, transfer-property=TRIGGERED-ON-CHANGE
          signal CAN4_ZRR_BCM_SMKR_Sta: start 35, 1 bit, big-endian, i-signal-type=PRIMITIVE, init-value=constant-reference=Init_CAN4_ZRR_BCM_SMKR_Sta, base-type=uint8, implementation-data-type=uint8, transfer-property=TRIGGERED-ON-CHANGE
          signal CAN4_ZRR_BCM_SRTLp_Sta: start 36, 1 bit, big-endian, i-signal-type=PRIMITIVE, init-value=constant-reference=Init_CAN4_ZRR_BCM_SRTLp_Sta, base-type=uint8, implementation-data-type=uint8, transfer-property=TRIGGERED-ON-CHANGE
          signal CAN4_ZRR_BCM_STOPSW2_Sta: start 39, 1 bit, big-endian, i-signal-type=PRIMITIVE, init-value=constant-reference=Init_CAN4_ZRR_BCM_STOPSW2_Sta, base-type=uint8, implementation-data-type=uint8, transfer-property=TRIGGERED-ON-CHANGE
          signal CAN4_ZRR_BCM_STOPSW_Sta: start 38, 1 bit, big-endian, i-signal-type=PRIMITIVE, init-value=constant-reference=Init_CAN4_ZRR_BCM_STOPSW_Sta, base-type=uint8, implementation-data-type=uint8, transfer-property=TRIGGERED-ON-CHANGE
          signal CAN4_ZRR_BCM_StopLight_Sta: start 32, 1 bit, big-endian, i-signal-type=PRIMITIVE, init-value=constant-reference=Init_CAN4_ZRR_BCM_StopLight_Sta, base-type=uint8, implementation-data-type=uint8, transfer-property=TRIGGERED-ON-CHANGE
          signal CAN4_ZRR_BCM_TurnBuzzer_Sta: start 11, 1 bit, big-endian, i-signal-type=PRIMITIVE, init-value=constant-reference=Init_CAN4_ZRR_BCM_TurnBuzzer_Sta, base-type=uint8, implementation-data-type=uint8, transfer-property=TRIGGERED-ON-CHANGE
      frame CAN4_zGW_CANRr1_C50_0: id 0x20A, frame-length=32, can-addressing-mode=STANDARD, can-fd-frame-support=true, can-frame-rx-behavior=CAN-FD, can-frame-tx-behavior=CAN-FD
        pdu CAN4_zGW_CANRr1_C50_0: length=32, minimum-delay=0.0, transmission-mode-true-timing=cyclic-timing=time-period=0.05, unused-bit-pattern=0
          mapping CAN4_SG_zGW_CANRr1_C50_0: i-signal-group=CAN4_SG_zGW_CANRr1_C50_0, start-position=0, transfer-property=PENDING
          signal CAN4_DCDC_En_Sta: start 75, 2 bit, little-endian, i-signal-type=PRIMITIVE, init-value=constant-reference=Init_CAN4_DCDC_En_Sta, base-type=uint8, implementation-data-type=uint8, transfer-property=PENDING
          signal CAN4_DCDC_ErrLv_Sta: start 72, 3 bit, little-endian, i-signal-type=PRIMITIVE, init-value=constant-reference=Init_CAN4_DCDC_ErrLv_Sta, base-type=uint8, implementation-data-type=uint8, transfer-property=PENDING
          signal CAN4_DCDC_LifeSig_Sta: start 88, 8 bit, little-endian, i-signal-type=PRIMITIVE, init-value=constant-reference=Init_CAN4_DCDC_LifeSig_Sta, base-type=uint8, implementation-data-type=uint8, transfer-property=PENDING
          signal CAN4_DCDC_OutVol_Sta: start 32, 16 bit, little-endian, i-signal-type=PRIMITIVE, init-value=constant-reference=Init_CAN4_DCDC_OutVol_Sta, base-type=uint16, implementation-data-type=uint16, transfer-property=PENDING
          signal CAN4_DCDC_Temp_Sta: start 16, 8 bit, little-endian, i-signal-type=PRIMITIVE, init-value=constant-reference=Init_CAN4_DCDC_Temp_Sta, base-type=uint8, implementation-data-type=uint8, transfer-property=PENDING
          signal CAN4_EAC_En_Sta: start 69, 2 bit, little-endian, i-signal-type=PRIMITIVE, init-value=constant-reference=Init_CAN4_EAC_En_Sta, base-type=uint8, implementation-data-type=uint8, transfer-property=PENDING
          signal CAN4_EAC_ErrLv_Sta: start 24, 3 bit, little-endian, i-signal-type=PRIMITIVE, init-value=constant-reference=Init_CAN4_EAC_ErrLv_Sta, base-type=uint8, implementation-data-type=uint8, transfer-property=PENDING
          signal CAN4_EAC_InvTemp_Sta: start 0, 8 bit, little-endian, i-signal-type=PRIMITIVE, init-value=constant-reference=Init_CAN4_EAC_InvTemp_Sta, base-type=uint8, implementation-data-type=uint8, transfer-property=PENDING
          signal CAN4_EAC_LifeSig_Sta: start 80, 8 bit, little-endian, i-signal-type=PRIMITIVE, init-value=constant-reference=Init_CAN4_EAC_LifeSig_Sta, base-type=uint8, implementation-data-type=uint8, transfer-property=PENDING
          signal CAN4_EHPS_En_Sta: start 67, 2 bit, little-endian, i-signal-type=PRIMITIVE, init-value=constant-reference=Init_CAN4_EHPS_En_Sta, base-type=uint8, implementation-data-type=uint8, transfer-property=PENDING
          signal CAN4_EHPS_ErrLv_Sta: start 64, 3 bit, little-endian, i-signal-type=PRIMITIVE, init-value=constant-reference=Init_CAN4_EHPS_ErrLv_Sta, base-type=uint8, implementation-data-type=uint8, transfer-property=PENDING
          signal CAN4_EHPS_InvTemp_Sta: start 8, 8 bit, little-endian, i-signal-type=PRIMITIVE, init-value=constant-reference=Init_CAN4_EHPS_InvTemp_Sta, base-type=uint8, implementation-data-type=uint8, transfer-property=PENDING
          signal CAN4_EHPS_LifeSig_Sta: start 112, 8 bit, little-endian, i-signal-type=PRIMITIVE, init-value=constant-reference=Init_CAN4_EHPS_LifeSig_Sta, base-type=uint8, implementation-data-type=uint8, transfer-property=PENDING
          signal CAN4_EHPS_MotorSpd_Sta: start 96, 16 bit, little-endian, i-signal-type=PRIMITIVE, init-value=constant-reference=Init_CAN4_EHPS_MotorSpd_Sta, base-type=uint16, implementation-data-type=uint16, transfer-property=PENDING
          signal CAN4_PDU_ACRly_Sta: start 56, 2 bit, little-endian, i-signal-type=PRIMITIVE, init-value=constant-reference=Init_CAN4_PDU_ACRly_Sta, base-type=uint8, implementation-data-type=uint8, transfer-property=PENDING
          signal CAN4_PDU_DCDCEACEHPSHVLoop_Sta: start 27, 2 bit, little-endian, i-signal-type=PRIMITIVE, init-value=constant-reference=Init_CAN4_PDU_DCDCEACEHPSHVLoop_Sta, base-type=uint8, implementation-data-type=uint8, transfer-property=PENDING
          signal CAN4_PDU_DCDCEACEHPSPreRly_Sta: start 29, 2 bit, little-endian, i-signal-type=PRIMITIVE, init-value=constant-reference=Init_CAN4_PDU_DCDCEACEHPSPreRly_Sta, base-type=uint8, implementation-data-type=uint8, transfer-property=PENDING
          signal CAN4_PDU_DCDCEACEHPSRly_Sta: start 60, 2 bit, little-endian, i-signal-type=PRIMITIVE, init-value=constant-reference=Init_CAN4_PDU_DCDCEACEHPSRly_Sta, base-type=uint8, implementation-data-type=uint8, transfer-property=PENDING
          signal CAN4_PDU_DeFogTMSRly_Sta: start 58, 2 bit, little-endian, i-signal-type=PRIMITIVE, init-value=constant-reference=Init_CAN4_PDU_DeFogTMSRly_Sta, base-type=uint8, implementation-data-type=uint8, transfer-property=PENDING
          signal CAN4_PDU_HVIL_Sta: start 62, 2 bit, little-endian, i-signal-type=PRIMITIVE, init-value=constant-reference=Init_CAN4_PDU_HVIL_Sta, base-type=uint8, implementation-data-type=uint8, transfer-property=PENDING
          signal CAN4_PDU_LifeSig_Sta: start 120, 8 bit, little-endian, i-signal-type=PRIMITIVE, init-value=constant-reference=Init_CAN4_PDU_LifeSig_Sta, base-type=uint8, implementation-data-type=uint8, transfer-property=PENDING
          signal CAN4_PDU_MCUHVLoop_Sta: start 54, 2 bit, little-endian, i-signal-type=PRIMITIVE, init-value=constant-reference=Init_CAN4_PDU_MCUHVLoop_Sta, base-type=uint8, implementation-data-type=uint8, transfer-property=PENDING
          signal CAN4_PDU_MCUPosRly_Sta: start 52, 2 bit, little-endian, i-signal-type=PRIMITIVE, init-value=constant-reference=Init_CAN4_PDU_MCUPosRly_Sta, base-type=uint8, implementation-data-type=uint8, transfer-property=PENDING
          signal CAN4_PDU_MCUPreRly_Sta: start 50, 2 bit, little-endian, i-signal-type=PRIMITIVE, init-value=constant-reference=Init_CAN4_PDU_MCUPreRly_Sta, base-type=uint8, implementation-data-type=uint8, transfer-property=PENDING
          signal CAN4_PDU_SelfChk_Sta: start 48, 2 bit, little-endian, i-signal-type=PRIMITIVE, init-value=constant-reference=Init_CAN4_PDU_SelfChk_Sta, base-type=uint8, implementation-data-type=uint8, transfer-property=PENDING
      frame CAN4_NMm_FUSION_TX: id 0x500, frame-length=8, can-addressing-mode=STANDARD, can-fd-frame-support=false, can-frame-rx-behavior=CAN-20, can-frame-tx-behavior=CAN-20
        nm pdu CAN4_NMm_FUSION_TX: length=8, unused-bit-pattern=0
      frame CAN4_NMm_FUSION_RX: id 0x500, frame-length=8, can-addressing-mode=STANDARD, can-fd-frame-support=false, can-frame-rx-behavior=CAN-20, can-frame-tx-behavior=CAN-20
        nm pdu CAN4_NMm_FUSION_RX: length=8, unused-bit-pattern=0
package /CAN4/ConstantSpecification
  171 x constant specification:
    Init_CAN4_DCDCEnDemand: value-spec=0
    Init_CAN4_EACSpdDemand: value-spec=10000
    Init_CAN4_FDC_CHA_EACEnDemand_Cmd: value-spec=0
    Init_CAN4_FDC_EHPS_EnDemand_Cmd: value-spec=0
    Init_CAN4_FDC_EHPS_SpdDemand_Cmd: value-spec=0
    Init_CAN4_VCULife2: value-spec=0
    Init_CAN4_ACHVPwrOnOffReq: value-spec=0
    Init_CAN4_MCUHVPwrOnOffReq: value-spec=0
    Init_CAN4_VCULife1: value-spec=0
    Init_CAN4_VCU_DCDCEACEHPSRlyEn_cmd: value-spec=0
    Init_CAN4_VCU_DeFogTMSRlyEn_cmd: value-spec=0
    Init_CAN4_SysPowerMode: value-spec=0
    Init_CAN4_VCUIGNSta: value-spec=0
    Init_CAN4_VCUIRCSta: value-spec=0
    Init_CAN4_FDC_BCM_BSD_Buzzer_Cmd: value-spec=0
    Init_CAN4_FDC_BCM_Brake_Cmd: value-spec=0
    Init_CAN4_FDC_BCM_CallBell_Cmd: value-spec=0
    Init_CAN4_FDC_BCM_DVRSignalL_Cmd: value-spec=0
    Init_CAN4_FDC_BCM_DVRSignalR_Cmd: value-spec=0
    Init_CAN4_FDC_BCM_EmExitSW_Sta: value-spec=0
    Init_CAN4_FDC_BCM_EmSV_Cmd: value-spec=0
    Init_CAN4_FDC_BCM_FDCloseSV_Cmd: value-spec=0
    Init_CAN4_FDC_BCM_FDOpenSV_Cmd: value-spec=0
    Init_CAN4_FDC_BCM_FDoor_Sta: value-spec=0
    Init_CAN4_FDC_BCM_HBeam_Cmd: value-spec=0
    Init_CAN4_FDC_BCM_InnerBuzzerMode_Sta: value-spec=0
    Init_CAN4_FDC_BCM_InnerBuzzer_Cmd: value-spec=0
    Init_CAN4_FDC_BCM_InnerCallBell_Cmd: value-spec=0
    Init_CAN4_FDC_BCM_LBSDR_Cmd: value-spec=0
    Init_CAN4_FDC_BCM_LBSDY_Cmd: value-spec=0
    Init_CAN4_FDC_BCM_LBeam_Cmd: value-spec=0
    Init_CAN4_FDC_BCM_LDRL_Cmd: value-spec=0
    Init_CAN4_FDC_BCM_LTurnLp_Cmd: value-spec=0
    Init_CAN4_FDC_BCM_MDCloseSV_Cmd: value-spec=0
    Init_CAN4_FDC_BCM_MDOpenSV_Cmd: value-spec=0
    Init_CAN4_FDC_BCM_MDoor_Sta: value-spec=0
    Init_CAN4_FDC_BCM_OutDoorOpenSW_Sta: value-spec=0
    Init_CAN4_FDC_BCM_PLamp_Cmd: value-spec=0
    Init_CAN4_FDC_BCM_RBSDR_Cmd: value-spec=0
    Init_CAN4_FDC_BCM_RBSDY_Cmd: value-spec=0
    Init_CAN4_FDC_BCM_RDRL_Cmd: value-spec=0
    Init_CAN4_FDC_BCM_RDoor_Sta: value-spec=0
    Init_CAN4_FDC_BCM_RFLamp_Cmd: value-spec=0
    Init_CAN4_FDC_BCM_RGear_Sta: value-spec=0
    Init_CAN4_FDC_BCM_RTurnLp_Cmd: value-spec=0
    Init_CAN4_FDC_BCM_RoomLpAmb_Cmd: value-spec=0
    Init_CAN4_FDC_BCM_SLTLp_Cmd: value-spec=0
    Init_CAN4_FDC_BCM_SMKL_Cmd: value-spec=0
    Init_CAN4_FDC_BCM_SMKR_Cmd: value-spec=0
    Init_CAN4_FDC_BCM_SRTLp_Cmd: value-spec=0
    Init_CAN4_FDC_BCM_STOPBALL_Cmd: value-spec=0
    Init_CAN4_FDC_BCM_Stop_IND_Cmd: value-spec=0
    Init_CAN4_FDC_BCM_TurnLpPattern_Sta: value-spec=0
    Init_CAN4_FDC_BCM_Washer_Cmd: value-spec=0
    Init_CAN4_FDC_BCM_WiperH_Cmd: value-spec=0
    Init_CAN4_FDC_BCM_WiperL_Cmd: value-spec=0
    Init_CAN4_VCUKeyStatus: value-spec=0
    Init_CAN4_FDC_BCM_FRoomLp_Cmd: value-spec=0
    Init_CAN4_FDC_BCM_MRoomLp_Cmd: value-spec=0
    Init_CAN4_FDC_BCM_RRoomLp_Cmd: value-spec=0
    Init_CAN4_FDC_THCM_CoolFanReq_Cmd: value-spec=0
    Init_CAN4_ParkBrakeSW: value-spec=0
    Init_CAN4_ZFR_CHASSIS_LiningWearFL_Sta: value-spec=0
    Init_CAN4_ZFR_CHASSIS_LiningWearFR_Sta: value-spec=0
    Init_CAN4_AirPressureFC2: value-spec=0
    Init_CAN4_ZFR_BCM_AutoLightSW_Sta: value-spec=0
    Init_CAN4_ZFR_BCM_BSD_Dimmer_Sta: value-spec=0
    Init_CAN4_ZFR_BCM_BacklightDuty_Sta: value-spec=0
    Init_CAN4_ZFR_BCM_Brake_Sta: value-spec=0
    Init_CAN4_ZFR_BCM_DVRMidDoor_Sta: value-spec=0
    Init_CAN4_ZFR_BCM_DVRSignalL_Sta: value-spec=0
    Init_CAN4_ZFR_BCM_DVRSignalR_Sta: value-spec=0
    Init_CAN4_ZFR_BCM_DVRSignalReverse_Sta: value-spec=0
    Init_CAN4_ZFR_BCM_HBeamSW_Sta: value-spec=0
    Init_CAN4_ZFR_BCM_HBeam_Sta: value-spec=0
    Init_CAN4_ZFR_BCM_HeadLpSW_Sta: value-spec=0
    Init_CAN4_ZFR_BCM_HornSW_Sta: value-spec=0
    Init_CAN4_ZFR_BCM_LBSDR_Sta: value-spec=0
    Init_CAN4_ZFR_BCM_LBSDY_Sta: value-spec=0
    Init_CAN4_ZFR_BCM_LBeam_Sta: value-spec=0
    Init_CAN4_ZFR_BCM_LDRL_Sta: value-spec=0
    Init_CAN4_ZFR_BCM_LFTurnLpC_Sta: value-spec=255
    Init_CAN4_ZFR_BCM_LFTurnLp_Sta: value-spec=0
    Init_CAN4_ZFR_BCM_LightSensorV_Sta: value-spec=0
    Init_CAN4_ZFR_BCM_PLamp_Sta: value-spec=0
    Init_CAN4_ZFR_BCM_PosLpSW_Sta: value-spec=0
    Init_CAN4_ZFR_BCM_RBSDR_Sta: value-spec=0
    Init_CAN4_ZFR_BCM_RBSDY_Sta: value-spec=0
    Init_CAN4_ZFR_BCM_RDRL_Sta: value-spec=0
    Init_CAN4_ZFR_BCM_RFTurnLpC_Sta: value-spec=255
    Init_CAN4_ZFR_BCM_RFTurnLp_Sta: value-spec=0
    Init_CAN4_ZFR_BCM_RFogLp_SW_Sta: value-spec=0
    Init_CAN4_ZFR_BCM_Seatbelt_Sta: value-spec=0
    Init_CAN4_ZFR_BCM_TurnBuzzer_Sta: value-spec=0
    Init_CAN4_ZFR_BCM_WasherSW_Sta: value-spec=0
    Init_CAN4_ZFR_BCM_Washer_Sta: value-spec=0
    Init_CAN4_ZFR_BCM_WiperAS_Sta: value-spec=0
    Init_CAN4_ZFR_BCM_WiperHSW_Sta: value-spec=0
    Init_CAN4_ZFR_BCM_WiperH_Sta: value-spec=0
    Init_CAN4_ZFR_BCM_WiperLSW_Sta: value-spec=0
    Init_CAN4_ZFR_BCM_WiperL_Sta: value-spec=0
    Init_CAN4_ZRR_CHASSIS_LiningWearRL_Sta: value-spec=0
    Init_CAN4_ZRR_CHASSIS_LiningWearRR_Sta: value-spec=0
    Init_CAN4_ZRR_BCM_AllDoor_Sta: value-spec=0
    Init_CAN4_AirPressurePC3: value-spec=0
    Init_CAN4_AirPressureRC1: value-spec=0
    Init_CAN4_FDC_CHASSIS_VCUEACPress_Sta: value-spec=0
    Init_CAN4_ZRR_BCM_BrakeLp_Sta: value-spec=0
    Init_CAN4_ZRR_BCM_CallingSW_Sta: value-spec=0
    Init_CAN4_ZRR_BCM_EmLight_Sta: value-spec=0
    Init_CAN4_ZRR_BCM_EmSV_Sta: value-spec=0
    Init_CAN4_ZRR_BCM_FDCloseSV_Sta: value-spec=0
    Init_CAN4_ZRR_BCM_FDOpenSV_Sta: value-spec=0
    Init_CAN4_ZRR_BCM_FDoorAP_Sta: value-spec=0
    Init_CAN4_ZRR_BCM_LRTurnLpC_Sta: value-spec=0
    Init_CAN4_ZRR_BCM_LRTurnLp_Sta: value-spec=0
    Init_CAN4_ZRR_BCM_MDCloseSV_Sta: value-spec=0
    Init_CAN4_ZRR_BCM_MDOpenSV_Sta: value-spec=0
    Init_CAN4_ZRR_BCM_MDoorAP_Sta: value-spec=0
    Init_CAN4_ZRR_BCM_PLamp_Sta: value-spec=0
    Init_CAN4_ZRR_BCM_RFLamp_Sta: value-spec=0
    Init_CAN4_ZRR_BCM_RRTurnLpC_Sta: value-spec=0
    Init_CAN4_ZRR_BCM_RRTurnLp_Sta: value-spec=0
    Init_CAN4_ZRR_BCM_ReverseBuz_Sta: value-spec=0
    Init_CAN4_ZRR_BCM_ReverseLp_Sta: value-spec=0
    Init_CAN4_ZRR_BCM_RoomLpAmb_Sta: value-spec=0
    Init_CAN4_ZRR_BCM_SLTLp_Sta: value-spec=0
    Init_CAN4_ZRR_BCM_SMKL_Sta: value-spec=0
    Init_CAN4_ZRR_BCM_SMKR_Sta: value-spec=0
    Init_CAN4_ZRR_BCM_SRTLp_Sta: value-spec=0
    Init_CAN4_ZRR_BCM_STOPSW2_Sta: value-spec=0
    Init_CAN4_ZRR_BCM_STOPSW_Sta: value-spec=0
    Init_CAN4_ZRR_BCM_StopLight_Sta: value-spec=0
    Init_CAN4_ZRR_BCM_TurnBuzzer_Sta: value-spec=0
    Init_CAN4_DCDC_En_Sta: value-spec=0
    Init_CAN4_DCDC_ErrLv_Sta: value-spec=0
    Init_CAN4_DCDC_LifeSig_Sta: value-spec=0
    Init_CAN4_DCDC_OutVol_Sta: value-spec=0
    Init_CAN4_DCDC_Temp_Sta: value-spec=0
    Init_CAN4_EAC_En_Sta: value-spec=0
    Init_CAN4_EAC_ErrLv_Sta: value-spec=0
    Init_CAN4_EAC_InvTemp_Sta: value-spec=0
    Init_CAN4_EAC_LifeSig_Sta: value-spec=0
    Init_CAN4_EHPS_En_Sta: value-spec=0
    Init_CAN4_EHPS_ErrLv_Sta: value-spec=0
    Init_CAN4_EHPS_InvTemp_Sta: value-spec=0
    Init_CAN4_EHPS_LifeSig_Sta: value-spec=0
    Init_CAN4_EHPS_MotorSpd_Sta: value-spec=0
    Init_CAN4_PDU_ACRly_Sta: value-spec=0
    Init_CAN4_PDU_DCDCEACEHPSHVLoop_Sta: value-spec=0
    Init_CAN4_PDU_DCDCEACEHPSPreRly_Sta: value-spec=0
    Init_CAN4_PDU_DCDCEACEHPSRly_Sta: value-spec=0
    Init_CAN4_PDU_DeFogTMSRly_Sta: value-spec=0
    Init_CAN4_PDU_HVIL_Sta: value-spec=0
    Init_CAN4_PDU_LifeSig_Sta: value-spec=0
    Init_CAN4_PDU_MCUHVLoop_Sta: value-spec=0
    Init_CAN4_PDU_MCUPosRly_Sta: value-spec=0
    Init_CAN4_PDU_MCUPreRly_Sta: value-spec=0
    Init_CAN4_PDU_SelfChk_Sta: value-spec=0
    Init_CAN4_SG_FD4_C100_0: value-spec=fields=[Init_CAN4_DCDCEnDemand, Init_CAN4_EACSpdDemand, Init_CAN4_FDC_CHA_EACEnDemand_Cmd, Init_CAN4_FDC_EHPS_EnDemand_Cmd, Init_CAN4_FDC_EHPS_SpdDemand_Cmd, Init_CAN4_VCULife2]
    Init_CAN4_SG_FD4_C10_0: value-spec=fields=[Init_CAN4_ACHVPwrOnOffReq, Init_CAN4_MCUHVPwrOnOffReq, Init_CAN4_VCULife1, Init_CAN4_VCU_DCDCEACEHPSRlyEn_cmd, Init_CAN4_VCU_DeFogTMSRlyEn_cmd]
    Init_CAN4_SG_FD4_C200_0: value-spec=fields=[Init_CAN4_SysPowerMode, Init_CAN4_VCUIGNSta, Init_CAN4_VCUIRCSta]
    Init_CAN4_SG_FD4_CE100_0: value-spec=fields=[Init_CAN4_FDC_BCM_BSD_Buzzer_Cmd, Init_CAN4_FDC_BCM_Brake_Cmd, Init_CAN4_FDC_BCM_CallBell_Cmd, Init_CAN4_FDC_BCM_DVRSignalL_Cmd, Init_CAN4_FDC_BCM_DVRSignalR_Cmd, Init_CAN4_FDC_BCM_EmExitSW_Sta, Init_CAN4_FDC_BCM_EmSV_Cmd, Init_CAN4_FDC_BCM_FDCloseSV_Cmd, Init_CAN4_FDC_BCM_FDOpenSV_Cmd, Init_CAN4_FDC_BCM_FDoor_Sta, Init_CAN4_FDC_BCM_HBeam_Cmd, Init_CAN4_FDC_BCM_InnerBuzzerMode_Sta, Init_CAN4_FDC_BCM_InnerBuzzer_Cmd, Init_CAN4_FDC_BCM_InnerCallBell_Cmd, Init_CAN4_FDC_BCM_LBSDR_Cmd, Init_CAN4_FDC_BCM_LBSDY_Cmd, Init_CAN4_FDC_BCM_LBeam_Cmd, Init_CAN4_FDC_BCM_LDRL_Cmd, Init_CAN4_FDC_BCM_LTurnLp_Cmd, Init_CAN4_FDC_BCM_MDCloseSV_Cmd, Init_CAN4_FDC_BCM_MDOpenSV_Cmd, Init_CAN4_FDC_BCM_MDoor_Sta, Init_CAN4_FDC_BCM_OutDoorOpenSW_Sta, Init_CAN4_FDC_BCM_PLamp_Cmd, Init_CAN4_FDC_BCM_RBSDR_Cmd, Init_CAN4_FDC_BCM_RBSDY_Cmd, Init_CAN4_FDC_BCM_RDRL_Cmd, Init_CAN4_FDC_BCM_RDoor_Sta, Init_CAN4_FDC_BCM_RFLamp_Cmd, Init_CAN4_FDC_BCM_RGear_Sta, Init_CAN4_FDC_BCM_RTurnLp_Cmd, Init_CAN4_FDC_BCM_RoomLpAmb_Cmd, Init_CAN4_FDC_BCM_SLTLp_Cmd, Init_CAN4_FDC_BCM_SMKL_Cmd, Init_CAN4_FDC_BCM_SMKR_Cmd, Init_CAN4_FDC_BCM_SRTLp_Cmd, Init_CAN4_FDC_BCM_STOPBALL_Cmd, Init_CAN4_FDC_BCM_Stop_IND_Cmd, Init_CAN4_FDC_BCM_TurnLpPattern_Sta, Init_CAN4_FDC_BCM_Washer_Cmd, Init_CAN4_FDC_BCM_WiperH_Cmd, Init_CAN4_FDC_BCM_WiperL_Cmd, Init_CAN4_VCUKeyStatus]
    Init_CAN4_SG_FD4_CE100_1: value-spec=fields=[Init_CAN4_FDC_BCM_FRoomLp_Cmd, Init_CAN4_FDC_BCM_MRoomLp_Cmd, Init_CAN4_FDC_BCM_RRoomLp_Cmd, Init_CAN4_FDC_THCM_CoolFanReq_Cmd]
    Init_CAN4_SG_ZFR_C100_0: value-spec=fields=constant-reference=Init_CAN4_ParkBrakeSW
    Init_CAN4_SG_ZFR_C5000_0: value-spec=fields=[Init_CAN4_ZFR_CHASSIS_LiningWearFL_Sta, Init_CAN4_ZFR_CHASSIS_LiningWearFR_Sta]
    Init_CAN4_SG_ZFR_CE100_0: value-spec=fields=[Init_CAN4_AirPressureFC2, Init_CAN4_ZFR_BCM_AutoLightSW_Sta, Init_CAN4_ZFR_BCM_BSD_Dimmer_Sta, Init_CAN4_ZFR_BCM_BacklightDuty_Sta, Init_CAN4_ZFR_BCM_Brake_Sta, Init_CAN4_ZFR_BCM_DVRMidDoor_Sta, Init_CAN4_ZFR_BCM_DVRSignalL_Sta, Init_CAN4_ZFR_BCM_DVRSignalR_Sta, Init_CAN4_ZFR_BCM_DVRSignalReverse_Sta, Init_CAN4_ZFR_BCM_HBeamSW_Sta, Init_CAN4_ZFR_BCM_HBeam_Sta, Init_CAN4_ZFR_BCM_HeadLpSW_Sta, Init_CAN4_ZFR_BCM_HornSW_Sta, Init_CAN4_ZFR_BCM_LBSDR_Sta, Init_CAN4_ZFR_BCM_LBSDY_Sta, Init_CAN4_ZFR_BCM_LBeam_Sta, Init_CAN4_ZFR_BCM_LDRL_Sta, Init_CAN4_ZFR_BCM_LFTurnLpC_Sta, Init_CAN4_ZFR_BCM_LFTurnLp_Sta, Init_CAN4_ZFR_BCM_LightSensorV_Sta, Init_CAN4_ZFR_BCM_PLamp_Sta, Init_CAN4_ZFR_BCM_PosLpSW_Sta, Init_CAN4_ZFR_BCM_RBSDR_Sta, Init_CAN4_ZFR_BCM_RBSDY_Sta, Init_CAN4_ZFR_BCM_RDRL_Sta, Init_CAN4_ZFR_BCM_RFTurnLpC_Sta, Init_CAN4_ZFR_BCM_RFTurnLp_Sta, Init_CAN4_ZFR_BCM_RFogLp_SW_Sta, Init_CAN4_ZFR_BCM_Seatbelt_Sta, Init_CAN4_ZFR_BCM_TurnBuzzer_Sta, Init_CAN4_ZFR_BCM_WasherSW_Sta, Init_CAN4_ZFR_BCM_Washer_Sta, Init_CAN4_ZFR_BCM_WiperAS_Sta, Init_CAN4_ZFR_BCM_WiperHSW_Sta, Init_CAN4_ZFR_BCM_WiperH_Sta, Init_CAN4_ZFR_BCM_WiperLSW_Sta, Init_CAN4_ZFR_BCM_WiperL_Sta]
    Init_CAN4_SG_ZRR_C5000_0: value-spec=fields=[Init_CAN4_ZRR_CHASSIS_LiningWearRL_Sta, Init_CAN4_ZRR_CHASSIS_LiningWearRR_Sta]
    Init_CAN4_SG_ZRR_CE100_0: value-spec=fields=constant-reference=Init_CAN4_ZRR_BCM_AllDoor_Sta
    Init_CAN4_SG_ZRR_CE100_1: value-spec=fields=[Init_CAN4_AirPressurePC3, Init_CAN4_AirPressureRC1, Init_CAN4_FDC_CHASSIS_VCUEACPress_Sta, Init_CAN4_ZRR_BCM_BrakeLp_Sta, Init_CAN4_ZRR_BCM_CallingSW_Sta, Init_CAN4_ZRR_BCM_EmLight_Sta, Init_CAN4_ZRR_BCM_EmSV_Sta, Init_CAN4_ZRR_BCM_FDCloseSV_Sta, Init_CAN4_ZRR_BCM_FDOpenSV_Sta, Init_CAN4_ZRR_BCM_FDoorAP_Sta, Init_CAN4_ZRR_BCM_LRTurnLpC_Sta, Init_CAN4_ZRR_BCM_LRTurnLp_Sta, Init_CAN4_ZRR_BCM_MDCloseSV_Sta, Init_CAN4_ZRR_BCM_MDOpenSV_Sta, Init_CAN4_ZRR_BCM_MDoorAP_Sta, Init_CAN4_ZRR_BCM_PLamp_Sta, Init_CAN4_ZRR_BCM_RFLamp_Sta, Init_CAN4_ZRR_BCM_RRTurnLpC_Sta, Init_CAN4_ZRR_BCM_RRTurnLp_Sta, Init_CAN4_ZRR_BCM_ReverseBuz_Sta, Init_CAN4_ZRR_BCM_ReverseLp_Sta, Init_CAN4_ZRR_BCM_RoomLpAmb_Sta, Init_CAN4_ZRR_BCM_SLTLp_Sta, Init_CAN4_ZRR_BCM_SMKL_Sta, Init_CAN4_ZRR_BCM_SMKR_Sta, Init_CAN4_ZRR_BCM_SRTLp_Sta, Init_CAN4_ZRR_BCM_STOPSW2_Sta, Init_CAN4_ZRR_BCM_STOPSW_Sta, Init_CAN4_ZRR_BCM_StopLight_Sta, Init_CAN4_ZRR_BCM_TurnBuzzer_Sta]
    Init_CAN4_SG_zGW_CANRr1_C50_0: value-spec=fields=[Init_CAN4_DCDC_En_Sta, Init_CAN4_DCDC_ErrLv_Sta, Init_CAN4_DCDC_LifeSig_Sta, Init_CAN4_DCDC_OutVol_Sta, Init_CAN4_DCDC_Temp_Sta, Init_CAN4_EAC_En_Sta, Init_CAN4_EAC_ErrLv_Sta, Init_CAN4_EAC_InvTemp_Sta, Init_CAN4_EAC_LifeSig_Sta, Init_CAN4_EHPS_En_Sta, Init_CAN4_EHPS_ErrLv_Sta, Init_CAN4_EHPS_InvTemp_Sta, Init_CAN4_EHPS_LifeSig_Sta, Init_CAN4_EHPS_MotorSpd_Sta, Init_CAN4_PDU_ACRly_Sta, Init_CAN4_PDU_DCDCEACEHPSHVLoop_Sta, Init_CAN4_PDU_DCDCEACEHPSPreRly_Sta, Init_CAN4_PDU_DCDCEACEHPSRly_Sta, Init_CAN4_PDU_DeFogTMSRly_Sta, Init_CAN4_PDU_HVIL_Sta, Init_CAN4_PDU_LifeSig_Sta, Init_CAN4_PDU_MCUHVLoop_Sta, Init_CAN4_PDU_MCUPosRly_Sta, Init_CAN4_PDU_MCUPreRly_Sta, Init_CAN4_PDU_SelfChk_Sta]
package /CAN4/ImplementationDataTypes
  12 x impl type, all with category=STRUCTURE:
    DT_CAN4_SG_FD4_C100_0
      6 x element, all with category=TYPE_REFERENCE:
        CAN4_DCDCEnDemand: implementation-data-type=uint8
        CAN4_EACSpdDemand: implementation-data-type=uint16
        CAN4_FDC_CHA_EACEnDemand_Cmd: implementation-data-type=uint8
        CAN4_FDC_EHPS_EnDemand_Cmd: implementation-data-type=uint8
        CAN4_FDC_EHPS_SpdDemand_Cmd: implementation-data-type=uint16
        CAN4_VCULife2: implementation-data-type=uint8
    DT_CAN4_SG_FD4_C10_0
      5 x element, all with category=TYPE_REFERENCE, implementation-data-type=uint8:
        CAN4_ACHVPwrOnOffReq
        CAN4_MCUHVPwrOnOffReq
        CAN4_VCULife1
        CAN4_VCU_DCDCEACEHPSRlyEn_cmd
        CAN4_VCU_DeFogTMSRlyEn_cmd
    DT_CAN4_SG_FD4_C200_0
      element CAN4_SysPowerMode: implementation-data-type=uint8
      element CAN4_VCUIGNSta: implementation-data-type=uint8
      element CAN4_VCUIRCSta: implementation-data-type=uint8
    DT_CAN4_SG_FD4_CE100_0
      43 x element, all with category=TYPE_REFERENCE, implementation-data-type=uint8:
        CAN4_FDC_BCM_BSD_Buzzer_Cmd
        CAN4_FDC_BCM_Brake_Cmd
        CAN4_FDC_BCM_CallBell_Cmd
        CAN4_FDC_BCM_DVRSignalL_Cmd
        CAN4_FDC_BCM_DVRSignalR_Cmd
        CAN4_FDC_BCM_EmExitSW_Sta
        CAN4_FDC_BCM_EmSV_Cmd
        CAN4_FDC_BCM_FDCloseSV_Cmd
        CAN4_FDC_BCM_FDOpenSV_Cmd
        CAN4_FDC_BCM_FDoor_Sta
        CAN4_FDC_BCM_HBeam_Cmd
        CAN4_FDC_BCM_InnerBuzzerMode_Sta
        CAN4_FDC_BCM_InnerBuzzer_Cmd
        CAN4_FDC_BCM_InnerCallBell_Cmd
        CAN4_FDC_BCM_LBSDR_Cmd
        CAN4_FDC_BCM_LBSDY_Cmd
        CAN4_FDC_BCM_LBeam_Cmd
        CAN4_FDC_BCM_LDRL_Cmd
        CAN4_FDC_BCM_LTurnLp_Cmd
        CAN4_FDC_BCM_MDCloseSV_Cmd
        CAN4_FDC_BCM_MDOpenSV_Cmd
        CAN4_FDC_BCM_MDoor_Sta
        CAN4_FDC_BCM_OutDoorOpenSW_Sta
        CAN4_FDC_BCM_PLamp_Cmd
        CAN4_FDC_BCM_RBSDR_Cmd
        CAN4_FDC_BCM_RBSDY_Cmd
        CAN4_FDC_BCM_RDRL_Cmd
        CAN4_FDC_BCM_RDoor_Sta
        CAN4_FDC_BCM_RFLamp_Cmd
        CAN4_FDC_BCM_RGear_Sta
        CAN4_FDC_BCM_RTurnLp_Cmd
        CAN4_FDC_BCM_RoomLpAmb_Cmd
        CAN4_FDC_BCM_SLTLp_Cmd
        CAN4_FDC_BCM_SMKL_Cmd
        CAN4_FDC_BCM_SMKR_Cmd
        CAN4_FDC_BCM_SRTLp_Cmd
        CAN4_FDC_BCM_STOPBALL_Cmd
        CAN4_FDC_BCM_Stop_IND_Cmd
        CAN4_FDC_BCM_TurnLpPattern_Sta
        CAN4_FDC_BCM_Washer_Cmd
        CAN4_FDC_BCM_WiperH_Cmd
        CAN4_FDC_BCM_WiperL_Cmd
        CAN4_VCUKeyStatus
    DT_CAN4_SG_FD4_CE100_1
      4 x element, all with category=TYPE_REFERENCE, implementation-data-type=uint8:
        CAN4_FDC_BCM_FRoomLp_Cmd
        CAN4_FDC_BCM_MRoomLp_Cmd
        CAN4_FDC_BCM_RRoomLp_Cmd
        CAN4_FDC_THCM_CoolFanReq_Cmd
    DT_CAN4_SG_ZFR_C100_0
      element CAN4_ParkBrakeSW: implementation-data-type=uint8
    DT_CAN4_SG_ZFR_C5000_0
      element CAN4_ZFR_CHASSIS_LiningWearFL_Sta: implementation-data-type=uint8
      element CAN4_ZFR_CHASSIS_LiningWearFR_Sta: implementation-data-type=uint8
    DT_CAN4_SG_ZFR_CE100_0
      37 x element, all with category=TYPE_REFERENCE, implementation-data-type=uint8:
        CAN4_AirPressureFC2
        CAN4_ZFR_BCM_AutoLightSW_Sta
        CAN4_ZFR_BCM_BSD_Dimmer_Sta
        CAN4_ZFR_BCM_BacklightDuty_Sta
        CAN4_ZFR_BCM_Brake_Sta
        CAN4_ZFR_BCM_DVRMidDoor_Sta
        CAN4_ZFR_BCM_DVRSignalL_Sta
        CAN4_ZFR_BCM_DVRSignalR_Sta
        CAN4_ZFR_BCM_DVRSignalReverse_Sta
        CAN4_ZFR_BCM_HBeamSW_Sta
        CAN4_ZFR_BCM_HBeam_Sta
        CAN4_ZFR_BCM_HeadLpSW_Sta
        CAN4_ZFR_BCM_HornSW_Sta
        CAN4_ZFR_BCM_LBSDR_Sta
        CAN4_ZFR_BCM_LBSDY_Sta
        CAN4_ZFR_BCM_LBeam_Sta
        CAN4_ZFR_BCM_LDRL_Sta
        CAN4_ZFR_BCM_LFTurnLpC_Sta
        CAN4_ZFR_BCM_LFTurnLp_Sta
        CAN4_ZFR_BCM_LightSensorV_Sta
        CAN4_ZFR_BCM_PLamp_Sta
        CAN4_ZFR_BCM_PosLpSW_Sta
        CAN4_ZFR_BCM_RBSDR_Sta
        CAN4_ZFR_BCM_RBSDY_Sta
        CAN4_ZFR_BCM_RDRL_Sta
        CAN4_ZFR_BCM_RFTurnLpC_Sta
        CAN4_ZFR_BCM_RFTurnLp_Sta
        CAN4_ZFR_BCM_RFogLp_SW_Sta
        CAN4_ZFR_BCM_Seatbelt_Sta
        CAN4_ZFR_BCM_TurnBuzzer_Sta
        CAN4_ZFR_BCM_WasherSW_Sta
        CAN4_ZFR_BCM_Washer_Sta
        CAN4_ZFR_BCM_WiperAS_Sta
        CAN4_ZFR_BCM_WiperHSW_Sta
        CAN4_ZFR_BCM_WiperH_Sta
        CAN4_ZFR_BCM_WiperLSW_Sta
        CAN4_ZFR_BCM_WiperL_Sta
    DT_CAN4_SG_ZRR_C5000_0
      element CAN4_ZRR_CHASSIS_LiningWearRL_Sta: implementation-data-type=uint8
      element CAN4_ZRR_CHASSIS_LiningWearRR_Sta: implementation-data-type=uint8
    DT_CAN4_SG_ZRR_CE100_0
      element CAN4_ZRR_BCM_AllDoor_Sta: implementation-data-type=uint8
    DT_CAN4_SG_ZRR_CE100_1
      30 x element, all with category=TYPE_REFERENCE, implementation-data-type=uint8:
        CAN4_AirPressurePC3
        CAN4_AirPressureRC1
        CAN4_FDC_CHASSIS_VCUEACPress_Sta
        CAN4_ZRR_BCM_BrakeLp_Sta
        CAN4_ZRR_BCM_CallingSW_Sta
        CAN4_ZRR_BCM_EmLight_Sta
        CAN4_ZRR_BCM_EmSV_Sta
        CAN4_ZRR_BCM_FDCloseSV_Sta
        CAN4_ZRR_BCM_FDOpenSV_Sta
        CAN4_ZRR_BCM_FDoorAP_Sta
        CAN4_ZRR_BCM_LRTurnLpC_Sta
        CAN4_ZRR_BCM_LRTurnLp_Sta
        CAN4_ZRR_BCM_MDCloseSV_Sta
        CAN4_ZRR_BCM_MDOpenSV_Sta
        CAN4_ZRR_BCM_MDoorAP_Sta
        CAN4_ZRR_BCM_PLamp_Sta
        CAN4_ZRR_BCM_RFLamp_Sta
        CAN4_ZRR_BCM_RRTurnLpC_Sta
        CAN4_ZRR_BCM_RRTurnLp_Sta
        CAN4_ZRR_BCM_ReverseBuz_Sta
        CAN4_ZRR_BCM_ReverseLp_Sta
        CAN4_ZRR_BCM_RoomLpAmb_Sta
        CAN4_ZRR_BCM_SLTLp_Sta
        CAN4_ZRR_BCM_SMKL_Sta
        CAN4_ZRR_BCM_SMKR_Sta
        CAN4_ZRR_BCM_SRTLp_Sta
        CAN4_ZRR_BCM_STOPSW2_Sta
        CAN4_ZRR_BCM_STOPSW_Sta
        CAN4_ZRR_BCM_StopLight_Sta
        CAN4_ZRR_BCM_TurnBuzzer_Sta
    DT_CAN4_SG_zGW_CANRr1_C50_0
      25 x element, all with category=TYPE_REFERENCE:
        CAN4_DCDC_En_Sta: implementation-data-type=uint8
        CAN4_DCDC_ErrLv_Sta: implementation-data-type=uint8
        CAN4_DCDC_LifeSig_Sta: implementation-data-type=uint8
        CAN4_DCDC_OutVol_Sta: implementation-data-type=uint16
        CAN4_DCDC_Temp_Sta: implementation-data-type=uint8
        CAN4_EAC_En_Sta: implementation-data-type=uint8
        CAN4_EAC_ErrLv_Sta: implementation-data-type=uint8
        CAN4_EAC_InvTemp_Sta: implementation-data-type=uint8
        CAN4_EAC_LifeSig_Sta: implementation-data-type=uint8
        CAN4_EHPS_En_Sta: implementation-data-type=uint8
        CAN4_EHPS_ErrLv_Sta: implementation-data-type=uint8
        CAN4_EHPS_InvTemp_Sta: implementation-data-type=uint8
        CAN4_EHPS_LifeSig_Sta: implementation-data-type=uint8
        CAN4_EHPS_MotorSpd_Sta: implementation-data-type=uint16
        CAN4_PDU_ACRly_Sta: implementation-data-type=uint8
        CAN4_PDU_DCDCEACEHPSHVLoop_Sta: implementation-data-type=uint8
        CAN4_PDU_DCDCEACEHPSPreRly_Sta: implementation-data-type=uint8
        CAN4_PDU_DCDCEACEHPSRly_Sta: implementation-data-type=uint8
        CAN4_PDU_DeFogTMSRly_Sta: implementation-data-type=uint8
        CAN4_PDU_HVIL_Sta: implementation-data-type=uint8
        CAN4_PDU_LifeSig_Sta: implementation-data-type=uint8
        CAN4_PDU_MCUHVLoop_Sta: implementation-data-type=uint8
        CAN4_PDU_MCUPosRly_Sta: implementation-data-type=uint8
        CAN4_PDU_MCUPreRly_Sta: implementation-data-type=uint8
        CAN4_PDU_SelfChk_Sta: implementation-data-type=uint8
